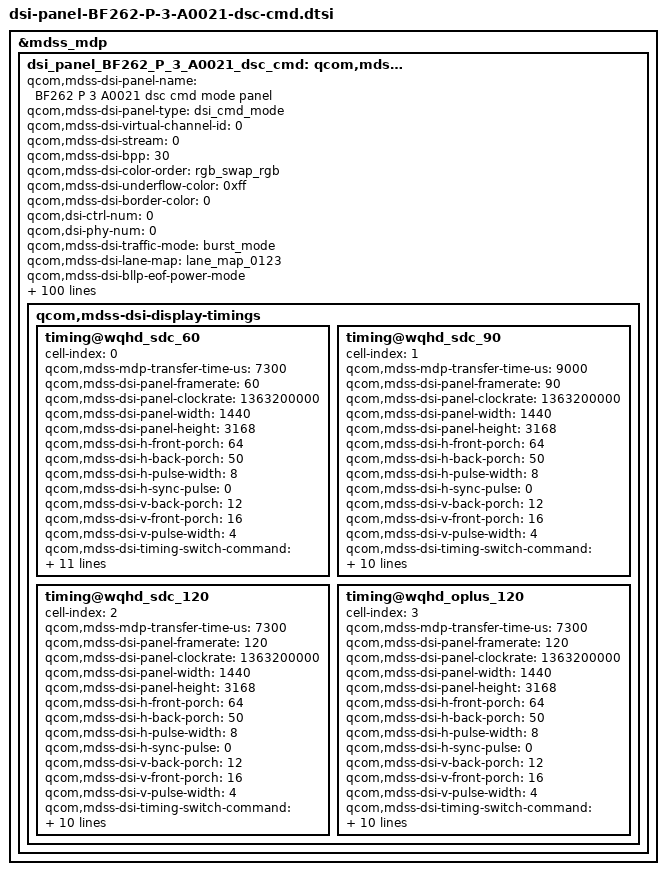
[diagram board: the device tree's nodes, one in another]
&mdss_mdp {
	dsi_panel_BF262_P_3_A0021_dsc_cmd: qcom,mdss_dsi_panel_BF262_P_3_A0021_dsc_cmd {
		qcom,mdss-dsi-panel-name = "BF262 P 3 A0021 dsc cmd mode panel";
		qcom,mdss-dsi-panel-type = "dsi_cmd_mode";
		qcom,mdss-dsi-virtual-channel-id = <0>;
		qcom,mdss-dsi-stream = <0>;
		qcom,mdss-dsi-bpp = <30>;
		qcom,mdss-dsi-color-order = "rgb_swap_rgb";
		qcom,mdss-dsi-underflow-color = <0xff>;
		qcom,mdss-dsi-border-color = <0>;
		qcom,dsi-ctrl-num = <0>;
		qcom,dsi-phy-num = <0>;
		qcom,mdss-dsi-traffic-mode = "burst_mode";
		qcom,mdss-dsi-lane-map = "lane_map_0123";
		qcom,mdss-dsi-bllp-eof-power-mode;
		qcom,mdss-dsi-bllp-power-mode;
		qcom,mdss-dsi-lane-0-state;
		qcom,mdss-dsi-lane-1-state;
		qcom,mdss-dsi-lane-2-state;
		qcom,mdss-dsi-lane-3-state;
		qcom,mdss-dsi-dma-trigger = "trigger_sw";
		qcom,mdss-dsi-mdp-trigger = "none";
		qcom,mdss-dsi-reset-sequence = <1 10>, <0 5>, <1 30>;
		qcom,mdss-pan-physical-width-dimension = <71>;
		qcom,mdss-pan-physical-height-dimension = <158>;
		qcom,mdss-dsi-te-check-enable;
		qcom,mdss-dsi-te-using-te-pin;
		qcom,mdss-dsi-te-pin-select = <1>;
		qcom,mdss-dsi-te-dcs-command = <1>;
		qcom,mdss-dsi-wr-mem-start = <0x2C>;
		qcom,mdss-dsi-wr-mem-continue = <0x3C>;
		//qcom,mdss-dsi-lp11-init;
		qcom,mdss-dsi-init-delay-us = <1000>;
		qcom,mdss-dsi-panel-jitter = <0x4 0x1>;
		qcom,dynamic-mode-switch-enabled;
		qcom,dynamic-mode-switch-type = "dynamic-resolution-switch-immediate";
		/* HDR Setting */
		qcom,mdss-dsi-panel-hdr-enabled;
		qcom,mdss-dsi-panel-hdr-color-primaries = <15635 16450 34000 16000 13250 34500 7500 3000>;
		qcom,mdss-dsi-panel-peak-brightness = <14000000>;
		qcom,mdss-dsi-panel-average-brightness = <2000000>;
		qcom,mdss-dsi-panel-blackness-level = <2000>;

		qcom,mdss-dsi-display-timings {
			timing@wqhd_sdc_60 {
				#include "dsi-panel-BF262-P-3-A0021-common.dtsi"
				cell-index = <0>;
				qcom,mdss-mdp-transfer-time-us = <7300>;
				qcom,mdss-dsi-panel-framerate = <60>;
				qcom,mdss-dsi-panel-clockrate = <1363200000>;
				qcom,mdss-dsi-panel-width = <1440>;
				qcom,mdss-dsi-panel-height = <3168>;
				qcom,mdss-dsi-h-front-porch = <64>;
				qcom,mdss-dsi-h-back-porch = <50>;
				qcom,mdss-dsi-h-pulse-width = <8>;
				qcom,mdss-dsi-h-sync-pulse = <0>;
				qcom,mdss-dsi-v-back-porch = <12>;
				qcom,mdss-dsi-v-front-porch = <16>;
				qcom,mdss-dsi-v-pulse-width = <4>;

				qcom,mdss-dsi-timing-switch-command = [
					15 00 00 40 00 00 02 FE 98
					15 00 00 40 00 00 02 CB 02
					15 00 00 40 00 00 02 FE 00
					15 00 00 40 00 00 02 8A 11
					15 00 00 40 00 00 02 FE 44
					15 00 00 40 00 00 02 49 00
					15 00 00 40 00 00 02 4E 01
					15 00 00 40 00 00 02 FE 72
					15 00 00 40 00 00 02 F7 48
					// SA
					15 00 00 40 00 00 02 FE 40
					15 00 00 00 00 00 02 92 65
				];
				qcom,mdss-dsi-on-command = [
					15 00 00 40 00 00 02 FE 44
					15 00 00 40 00 00 02 00 88
					15 00 00 40 00 00 02 75 00
					15 00 00 40 00 00 02 01 02
					15 00 00 40 00 00 02 02 01
					15 00 00 40 00 00 02 03 33
					15 00 00 40 00 00 02 04 33
					15 00 00 40 00 00 02 05 05
					15 00 00 40 00 00 02 06 0B
					15 00 00 40 00 00 02 07 17
					15 00 00 40 00 00 02 08 77
					15 00 00 40 00 00 02 09 00
					15 00 00 40 00 00 02 0A 00
					15 00 00 40 00 00 02 0B 00
					15 00 00 40 00 00 02 0C 00
					15 00 00 40 00 00 02 0D 23
					15 00 00 40 00 00 02 0E 30
					15 00 00 40 00 00 02 0F 00
					15 00 00 40 00 00 02 10 00
					15 00 00 40 00 00 02 11 11
					15 00 00 40 00 00 02 12 11
					15 00 00 40 00 00 02 13 11
					15 00 00 40 00 00 02 14 11
					15 00 00 40 00 00 02 15 02
					15 00 00 40 00 00 02 16 08
					15 00 00 40 00 00 02 17 11
					15 00 00 40 00 00 02 18 59
					15 00 00 40 00 00 02 19 00
					15 00 00 40 00 00 02 1A 00
					15 00 00 40 00 00 02 1B 00
					15 00 00 40 00 00 02 1C 00
					15 00 00 40 00 00 02 1D 23
					15 00 00 40 00 00 02 1E 30
					15 00 00 40 00 00 02 1F 11
					15 00 00 40 00 00 02 20 11
					15 00 00 40 00 00 02 21 11
					15 00 00 40 00 00 02 22 11
					15 00 00 40 00 00 02 23 11
					15 00 00 40 00 00 02 24 11
					15 00 00 40 00 00 02 25 05
					15 00 00 40 00 00 02 26 0B
					15 00 00 40 00 00 02 27 17
					15 00 00 40 00 00 02 28 77
					15 00 00 40 00 00 02 29 00
					15 00 00 40 00 00 02 2A 00
					15 00 00 40 00 00 02 2B 00
					15 00 00 40 00 00 02 2D 00
					15 00 00 40 00 00 02 2F 23
					15 00 00 40 00 00 02 30 30
					15 00 00 40 00 00 02 31 00
					15 00 00 40 00 00 02 32 00
					15 00 00 40 00 00 02 33 11
					15 00 00 40 00 00 02 34 11
					15 00 00 40 00 00 02 35 11
					15 00 00 40 00 00 02 36 11
					15 00 00 40 00 00 02 37 02
					15 00 00 40 00 00 02 38 08
					15 00 00 40 00 00 02 39 11
					15 00 00 40 00 00 02 3A 59
					15 00 00 40 00 00 02 3B 00
					15 00 00 40 00 00 02 3D 00
					15 00 00 40 00 00 02 3F 00
					15 00 00 40 00 00 02 40 00
					15 00 00 40 00 00 02 41 23
					15 00 00 40 00 00 02 42 30
					15 00 00 40 00 00 02 43 11
					15 00 00 40 00 00 02 44 11
					15 00 00 40 00 00 02 45 11
					15 00 00 40 00 00 02 46 11
					15 00 00 40 00 00 02 47 11
					15 00 00 40 00 00 02 48 11
					15 00 00 40 00 00 02 69 00
					15 00 00 40 00 00 02 6A 00
					15 00 00 40 00 00 02 6B 00
					15 00 00 40 00 00 02 6C 00
					15 00 00 40 00 00 02 6D 00
					15 00 00 40 00 00 02 6E 00
					15 00 00 40 00 00 02 6F 00
					15 00 00 40 00 00 02 70 00
					15 00 00 40 00 00 02 80 47
					15 00 00 40 00 00 02 81 02
					15 00 00 40 00 00 02 82 05
					15 00 00 40 00 00 02 83 1D
					15 00 00 40 00 00 02 84 00
					15 00 00 40 00 00 02 85 00
					15 00 00 40 00 00 02 86 00
					15 00 00 40 00 00 02 87 00
					15 00 00 40 00 00 02 88 00
					15 00 00 40 00 00 02 89 00
					15 00 00 40 00 00 02 8A 00
					15 00 00 40 00 00 02 8B 21
					15 00 00 40 00 00 02 8C 10
					15 00 00 40 00 00 02 8D 00
					15 00 00 40 00 00 02 8E 00
					15 00 00 40 00 00 02 8F 11
					15 00 00 40 00 00 02 90 11
					15 00 00 40 00 00 02 91 11
					15 00 00 40 00 00 02 92 11
					15 00 00 40 00 00 02 49 0B
					15 00 00 40 00 00 02 4A 06
					15 00 00 40 00 00 02 4B C0
					15 00 00 40 00 00 02 4C 00
					15 00 00 40 00 00 02 4D 00
					15 00 00 40 00 00 02 4E 00
					15 00 00 40 00 00 02 4F 00
					15 00 00 40 00 00 02 50 00
					15 00 00 40 00 00 02 51 00
					15 00 00 40 00 00 02 52 77
					15 00 00 40 00 00 02 53 59
					15 00 00 40 00 00 02 54 77
					15 00 00 40 00 00 02 55 59
					15 00 00 40 00 00 02 56 00
					15 00 00 40 00 00 02 58 00
					15 00 00 40 00 00 02 59 00
					15 00 00 40 00 00 02 5A 00
					15 00 00 40 00 00 02 5B 00
					15 00 00 40 00 00 02 5C 00
					15 00 00 40 00 00 02 5D 00
					15 00 00 40 00 00 02 71 00
					15 00 00 40 00 00 02 72 00
					15 00 00 40 00 00 02 73 00
					15 00 00 40 00 00 02 74 00
					15 00 00 40 00 00 02 5E 00
					15 00 00 40 00 00 02 5F 00
					15 00 00 40 00 00 02 60 00
					15 00 00 40 00 00 02 61 12
					15 00 00 40 00 00 02 62 30
					15 00 00 40 00 00 02 63 00
					15 00 00 40 00 00 02 64 00
					15 00 00 40 00 00 02 65 00
					15 00 00 40 00 00 02 76 C2
					15 00 00 40 00 00 02 77 E8
					15 00 00 40 00 00 02 FE 43
					15 00 00 40 00 00 02 64 15
					15 00 00 40 00 00 02 63 FE
					15 00 00 40 00 00 02 66 00
					15 00 00 40 00 00 02 67 11
					15 00 00 40 00 00 02 68 11
					15 00 00 40 00 00 02 69 33
					15 00 00 40 00 00 02 6A 33
					15 00 00 40 00 00 02 6B 00
					15 00 00 40 00 00 02 6C 00
					15 00 00 40 00 00 02 6D 00
					15 00 00 40 00 00 02 6E 00
					15 00 00 40 00 00 02 6F 00
					15 00 00 40 00 00 02 70 00
					15 00 00 40 00 00 02 71 00
					15 00 00 40 00 00 02 72 00
					15 00 00 40 00 00 02 73 00
					15 00 00 40 00 00 02 74 00
					15 00 00 40 00 00 02 75 00
					15 00 00 40 00 00 02 76 00
					15 00 00 40 00 00 02 77 00
					15 00 00 40 00 00 02 78 00
					15 00 00 40 00 00 02 79 00
					15 00 00 40 00 00 02 7A 00
					15 00 00 40 00 00 02 7B 00
					15 00 00 40 00 00 02 7C 00
					15 00 00 40 00 00 02 7D 00
					15 00 00 40 00 00 02 7E 00
					15 00 00 40 00 00 02 7F 00
					15 00 00 40 00 00 02 80 00
					15 00 00 40 00 00 02 81 00
					15 00 00 40 00 00 02 82 00
					15 00 00 40 00 00 02 83 00
					15 00 00 40 00 00 02 84 00
					15 00 00 40 00 00 02 85 00
					15 00 00 40 00 00 02 86 00
					15 00 00 40 00 00 02 87 00
					15 00 00 40 00 00 02 88 00
					15 00 00 40 00 00 02 89 00
					15 00 00 40 00 00 02 8A 00
					15 00 00 40 00 00 02 8B 21
					15 00 00 40 00 00 02 8C 16
					15 00 00 40 00 00 02 8D 0B
					15 00 00 40 00 00 02 8E 00
					15 00 00 40 00 00 02 8F 00
					15 00 00 40 00 00 02 90 00
					15 00 00 40 00 00 02 91 00
					15 00 00 40 00 00 02 92 00
					15 00 00 40 00 00 02 93 00
					15 00 00 40 00 00 02 94 00
					15 00 00 40 00 00 02 95 00
					15 00 00 40 00 00 02 96 00
					15 00 00 40 00 00 02 97 00
					15 00 00 40 00 00 02 98 00
					15 00 00 40 00 00 02 99 00
					15 00 00 40 00 00 02 9A 00
					15 00 00 40 00 00 02 9B 00
					15 00 00 40 00 00 02 9C 00
					15 00 00 40 00 00 02 9D 00
					15 00 00 40 00 00 02 9E 00
					15 00 00 40 00 00 02 9F 00
					15 00 00 40 00 00 02 A0 00
					15 00 00 40 00 00 02 A2 00
					15 00 00 40 00 00 02 A3 00
					15 00 00 40 00 00 02 A4 00
					15 00 00 40 00 00 02 A5 00
					15 00 00 40 00 00 02 A6 00
					15 00 00 40 00 00 02 A7 00
					15 00 00 40 00 00 02 A9 00
					15 00 00 40 00 00 02 AA 00
					15 00 00 40 00 00 02 AB 00
					15 00 00 40 00 00 02 AC 00
					15 00 00 40 00 00 02 AD 21
					15 00 00 40 00 00 02 AE 16
					15 00 00 40 00 00 02 AF 0B
					15 00 00 40 00 00 02 B0 00
					15 00 00 40 00 00 02 B1 00
					15 00 00 40 00 00 02 B2 00
					15 00 00 40 00 00 02 B3 00
					15 00 00 40 00 00 02 B4 00
					15 00 00 40 00 00 02 B5 00
					15 00 00 40 00 00 02 B6 00
					15 00 00 40 00 00 02 B7 00
					15 00 00 40 00 00 02 B8 00
					15 00 00 40 00 00 02 B9 00
					15 00 00 40 00 00 02 BA 00
					15 00 00 40 00 00 02 BB 00
					15 00 00 40 00 00 02 BC 00
					15 00 00 40 00 00 02 BD 00
					15 00 00 40 00 00 02 BE 00
					15 00 00 40 00 00 02 BF 00
					15 00 00 40 00 00 02 C0 00
					15 00 00 40 00 00 02 C1 00
					15 00 00 40 00 00 02 C2 00
					15 00 00 40 00 00 02 C3 00
					15 00 00 40 00 00 02 C4 00
					15 00 00 40 00 00 02 C5 00
					15 00 00 40 00 00 02 C6 00
					15 00 00 40 00 00 02 C7 00
					15 00 00 40 00 00 02 C8 00
					15 00 00 40 00 00 02 C9 00
					15 00 00 40 00 00 02 CA 00
					15 00 00 40 00 00 02 CB 00
					15 00 00 40 00 00 02 CC 00
					15 00 00 40 00 00 02 CD 21
					15 00 00 40 00 00 02 CE 16
					15 00 00 40 00 00 02 CF 0B
					15 00 00 40 00 00 02 D0 00
					15 00 00 40 00 00 02 D1 00
					15 00 00 40 00 00 02 D2 00
					15 00 00 40 00 00 02 D3 00
					15 00 00 40 00 00 02 D4 00
					15 00 00 40 00 00 02 D5 00
					15 00 00 40 00 00 02 D6 00
					15 00 00 40 00 00 02 D7 00
					15 00 00 40 00 00 02 D8 00
					15 00 00 40 00 00 02 D9 00
					15 00 00 40 00 00 02 DA 00
					15 00 00 40 00 00 02 DB 00
					15 00 00 40 00 00 02 DC 00
					15 00 00 40 00 00 02 DD 00
					15 00 00 40 00 00 02 DE 00
					15 00 00 40 00 00 02 DF 00
					15 00 00 40 00 00 02 E0 00
					15 00 00 40 00 00 02 E1 00
					15 00 00 40 00 00 02 E2 00
					15 00 00 40 00 00 02 E3 00
					15 00 00 40 00 00 02 E4 00
					15 00 00 40 00 00 02 E5 00
					15 00 00 40 00 00 02 E6 00
					15 00 00 40 00 00 02 E7 00
					15 00 00 40 00 00 02 E8 00
					15 00 00 40 00 00 02 E9 00
					15 00 00 40 00 00 02 EA 00
					15 00 00 40 00 00 02 EB 00
					15 00 00 40 00 00 02 EC 00
					15 00 00 40 00 00 02 FE 6A
					15 00 00 40 00 00 02 4E 00
					15 00 00 40 00 00 02 4F 00
					15 00 00 40 00 00 02 50 00
					15 00 00 40 00 00 02 51 00
					15 00 00 40 00 00 02 52 00
					15 00 00 40 00 00 02 53 00
					15 00 00 40 00 00 02 54 00
					15 00 00 40 00 00 02 55 00
					15 00 00 40 00 00 02 56 00
					15 00 00 40 00 00 02 58 00
					15 00 00 40 00 00 02 59 00
					15 00 00 40 00 00 02 5A 00
					15 00 00 40 00 00 02 5B 00
					15 00 00 40 00 00 02 5C 00
					15 00 00 40 00 00 02 5D 00
					15 00 00 40 00 00 02 5E 00
					15 00 00 40 00 00 02 FE 44
					15 00 00 40 00 00 02 78 07
					15 00 00 40 00 00 02 79 80
					15 00 00 40 00 00 02 66 00
					15 00 00 40 00 00 02 67 00
					15 00 00 40 00 00 02 FE 72
					15 00 00 40 00 00 02 F8 60
					15 00 00 40 00 00 02 33 03
					15 00 00 40 00 00 02 FE 98
					15 00 00 40 00 00 02 02 04
					15 00 00 40 00 00 02 03 68
					15 00 00 40 00 00 02 FE 40
					15 00 00 40 00 00 02 BC 02
					15 00 00 40 00 00 02 FE 98
					15 00 00 40 00 00 02 7D 10
					15 00 00 40 00 00 02 C4 8E
					15 00 00 40 00 00 02 FE 40
					15 00 00 40 00 00 02 92 65
					15 00 00 40 00 00 02 93 67
					15 00 00 40 00 00 02 FE 98
					15 00 00 40 00 00 02 CC 04
					15 00 00 40 00 00 02 CD 00
					15 00 00 40 00 00 02 CE E8
					15 00 00 40 00 00 02 CB 01
					15 00 00 40 00 00 02 C7 8A
					15 00 00 40 00 00 02 C6 80
					15 00 00 40 00 00 02 C5 00
					15 00 00 40 00 00 02 FE 98
					15 00 00 40 00 00 02 CB 01
					15 00 00 40 00 00 02 FE 45
					15 00 00 40 00 00 02 B2 78
					15 00 00 40 00 00 02 FE 72
					15 00 00 40 00 00 02 F7 48
					15 00 00 40 00 00 02 FE 00
					15 00 00 40 00 00 02 8A 11
					15 00 00 40 00 00 02 FE 44
					15 00 00 40 00 00 02 49 00
					15 00 00 40 00 00 02 4E 00
					15 00 00 40 00 00 02 FE 00
					15 00 00 40 00 00 02 2F 04
					15 00 00 40 00 00 02 FA 01
					15 00 00 40 00 00 02 C2 08
					15 00 00 40 00 00 02 35 00
					15 00 00 00 00 00 02 51 0D
					//60Hz
					/*ESD*/
					15 00 00 40 00 00 02 FE D4
					15 00 00 40 00 00 02 40 03
					15 00 00 40 00 00 02 FE FD
					15 00 00 40 00 00 02 80 06
					15 00 00 40 00 00 02 83 00
					15 00 00 40 00 00 02 FE A1
					15 00 00 40 00 00 02 B3 1F
					15 00 00 40 00 00 02 74 72
					15 00 00 40 00 00 02 C3 83
					15 00 00 40 00 00 02 C4 FF
					15 00 00 00 00 00 02 C5 7F
					//init code
					15 00 00 40 00 00 02 FE 42
					15 00 00 40 00 00 02 18 76
					15 00 00 40 00 00 02 FE 40
					15 00 00 40 00 00 02 BF BA
					15 00 00 40 00 00 02 FE 98
					15 00 00 40 00 00 02 2F 05
					15 00 00 40 00 00 02 FE 40
					15 00 00 40 00 00 02 BE 99
					15 00 00 40 00 00 02 FE 42
					15 00 00 40 00 00 02 1A 80
					15 00 00 40 00 00 02 19 00
					15 00 00 40 00 00 02 3B 65
					15 00 00 40 00 00 02 3D 00
					15 00 00 40 00 00 02 3F 00
					15 00 00 40 00 00 02 41 70
					15 00 00 40 00 00 02 43 00
					15 00 00 40 00 00 02 44 04
					15 00 00 40 00 00 02 FE 40
					15 00 00 40 00 00 02 64 60
					15 00 00 40 00 00 02 65 EC
					15 00 00 40 00 00 02 01 09
					15 00 00 40 00 00 02 FE D0
					15 00 00 40 00 00 02 86 14
					15 00 00 40 00 00 02 84 14
					15 00 00 40 00 00 02 85 01
					15 00 00 40 00 00 02 FE 99
					15 00 00 40 00 00 02 1B 14
					15 00 00 40 00 00 02 FE D0
					15 00 00 40 00 00 02 90 D0
					15 00 00 40 00 00 02 91 0A
					15 00 00 40 00 00 02 FE D4
					15 00 00 40 00 00 02 05 00
					15 00 00 40 00 00 02 FE D6
					15 00 00 40 00 00 02 17 00
					15 00 00 40 00 00 02 00 00
					15 00 00 40 00 00 02 09 00
					15 00 00 40 00 00 02 01 00
					15 00 00 40 00 00 02 02 FF
					15 00 00 40 00 00 02 05 FF
					15 00 00 40 00 00 02 03 0C
					15 00 00 40 00 00 02 04 02
					15 00 00 40 00 00 02 06 FF
					15 00 00 40 00 00 02 07 0C
					15 00 00 40 00 00 02 08 00
					15 00 00 40 00 00 02 FE 28
					15 00 00 40 00 00 02 05 01
					15 00 00 40 00 00 02 06 68
					15 00 00 40 00 00 02 FE 97
					15 00 00 40 00 00 02 40 01
					15 00 00 40 00 00 02 3D 05
					15 00 00 40 00 00 02 3F A0
					15 00 00 40 00 00 02 FE 1A
					15 00 00 40 00 00 02 04 01
					15 00 00 40 00 00 02 54 01
					15 00 00 40 00 00 02 FE 49
					15 00 00 40 00 00 02 5D 00
					15 00 00 40 00 00 02 54 17
					15 00 00 40 00 00 02 FE 1A
					15 00 00 40 00 00 02 62 80
					15 00 00 40 00 00 02 63 01
					15 00 00 40 00 00 02 64 01
					15 00 00 40 00 00 02 65 68
					15 00 00 40 00 00 02 36 50
					15 00 00 40 00 00 02 38 00
					15 00 00 40 00 00 02 1C 30
					15 00 00 40 00 00 02 FE 98
					15 00 00 40 00 00 02 0E A2
					15 00 00 40 00 00 02 FE 49
					15 00 00 40 00 00 02 79 81
					15 00 00 40 00 00 02 FE 1A
					15 00 00 40 00 00 02 34 13
					15 00 00 40 00 00 02 FE 49
					15 00 00 40 00 00 02 92 FF
					15 00 00 40 00 00 02 62 02
					15 00 00 40 00 00 02 63 01
					15 00 00 40 00 00 02 64 00
					15 00 00 40 00 00 02 0E 01
					15 00 00 40 00 00 02 11 22
					15 00 00 40 00 00 02 12 01
					15 00 00 40 00 00 02 B3 01
					15 00 00 40 00 00 02 68 09
					15 00 00 40 00 00 02 65 09
					15 00 00 40 00 00 02 66 09
					15 00 00 40 00 00 02 67 09
					15 00 00 40 00 00 02 0F 09
					15 00 00 40 00 00 02 6E 20
					15 00 00 40 00 00 02 72 58
					15 00 00 40 00 00 02 6D 00
					15 00 00 40 00 00 02 6F 58
					15 00 00 40 00 00 02 70 58
					15 00 00 40 00 00 02 71 58
					15 00 00 40 00 00 02 14 A9
					15 00 00 40 00 00 02 BD 01
					15 00 00 40 00 00 02 05 C1
					15 00 00 40 00 00 02 94 01
					15 00 00 40 00 00 02 06 C1
					15 00 00 40 00 00 02 B8 22
					15 00 00 40 00 00 02 BC 00
					15 00 00 40 00 00 02 BA 00
					15 00 00 40 00 00 02 1B 02
					15 00 00 40 00 00 02 1C 02
					15 00 00 40 00 00 02 1F 00
					15 00 00 40 00 00 02 20 00
					15 00 00 40 00 00 02 FE 98
					15 00 00 40 00 00 02 CF 00
					15 00 00 40 00 00 02 D0 AA
					15 00 00 40 00 00 02 FE 49
					15 00 00 40 00 00 02 9D 12
					15 00 00 40 00 00 02 B2 00
					15 00 00 40 00 00 02 FE D6
					15 00 00 40 00 00 02 9D 80
					15 00 00 40 00 00 02 FE 99
					15 00 00 40 00 00 02 1E 00
					15 00 00 40 00 00 02 1F 00
					15 00 00 40 00 00 02 FE 98
					15 00 00 40 00 00 02 0D C0
					15 00 00 40 00 00 02 FE D0
					15 00 00 40 00 00 02 C7 00
					15 00 00 40 00 00 02 C8 00
					15 00 00 40 00 00 02 FE 98
					15 00 00 40 00 00 02 0F FF
					15 00 00 40 00 00 02 FE 1A
					15 00 00 40 00 00 02 71 00
					15 00 00 40 00 00 02 FE 98
					15 00 00 40 00 00 02 11 08
					15 00 00 40 00 00 02 FE 72
					15 00 00 40 00 00 02 9B 00
					15 00 00 40 00 00 02 FE 6B
					15 00 00 40 00 00 02 03 10
					15 00 00 40 00 00 02 04 00
					15 00 00 40 00 00 02 FE 82
					15 00 00 40 00 00 02 C8 08
					15 00 00 40 00 00 02 FE 58
					15 00 00 40 00 00 02 C5 00
					15 00 00 40 00 00 02 FE D4
					15 00 00 40 00 00 02 04 06
					15 00 00 40 00 00 02 FE 98
					15 00 00 40 00 00 02 30 26
					15 00 00 40 00 00 02 31 80
					15 00 00 40 00 00 02 FE 49
					15 00 00 40 00 00 02 9D 12
					15 00 00 40 00 00 02 B2 08
					//ODC Off
					15 00 00 40 00 00 02 FE 82
					15 00 00 40 00 00 02 00 50
					//----Resolution_VESA END----
					15 00 00 40 00 00 02 FE D2
					15 00 00 40 00 00 02 97 00
					15 00 00 40 00 00 02 36 11
					15 00 00 40 00 00 02 39 AB
					15 00 00 40 00 00 02 3A 30
					15 00 00 40 00 00 02 3B 80
					15 00 00 40 00 00 02 3D 0C
					15 00 00 40 00 00 02 3F 60
					15 00 00 40 00 00 02 40 05
					15 00 00 40 00 00 02 41 A0
					15 00 00 40 00 00 02 42 00
					15 00 00 40 00 00 02 43 90
					15 00 00 40 00 00 02 44 02
					15 00 00 40 00 00 02 45 D0
					15 00 00 40 00 00 02 46 02
					15 00 00 40 00 00 02 47 D0
					15 00 00 40 00 00 02 48 02
					15 00 00 40 00 00 02 49 00
					15 00 00 40 00 00 02 4A 02
					15 00 00 40 00 00 02 4B 68
					15 00 00 40 00 00 02 4D 20
					15 00 00 40 00 00 02 4E 10
					15 00 00 40 00 00 02 4F 16
					15 00 00 40 00 00 02 50 00
					15 00 00 40 00 00 02 51 0A
					15 00 00 40 00 00 02 53 0C
					15 00 00 40 00 00 02 54 00
					15 00 00 40 00 00 02 55 AC
					15 00 00 40 00 00 02 56 00
					15 00 00 40 00 00 02 58 88
					15 00 00 40 00 00 02 59 18
					15 00 00 40 00 00 02 5A 00
					15 00 00 40 00 00 02 5B 10
					15 00 00 40 00 00 02 5C F0
					15 00 00 40 00 00 02 5D 07
					15 00 00 40 00 00 02 5E 10
					15 00 00 40 00 00 02 5F 20
					15 00 00 40 00 00 02 60 00
					15 00 00 40 00 00 02 61 06
					15 00 00 40 00 00 02 62 0F
					15 00 00 40 00 00 02 63 0F
					15 00 00 40 00 00 02 64 33
					15 00 00 40 00 00 02 65 0E
					15 00 00 40 00 00 02 66 1C
					15 00 00 40 00 00 02 67 2A
					15 00 00 40 00 00 02 68 38
					15 00 00 40 00 00 02 69 46
					15 00 00 40 00 00 02 6A 54
					15 00 00 40 00 00 02 6B 62
					15 00 00 40 00 00 02 6C 69
					15 00 00 40 00 00 02 6D 70
					15 00 00 40 00 00 02 6E 77
					15 00 00 40 00 00 02 6F 79
					15 00 00 40 00 00 02 70 7B
					15 00 00 40 00 00 02 71 7D
					15 00 00 40 00 00 02 72 7E
					15 00 00 40 00 00 02 73 02
					15 00 00 40 00 00 02 74 02
					15 00 00 40 00 00 02 75 22
					15 00 00 40 00 00 02 76 00
					15 00 00 40 00 00 02 77 2A
					15 00 00 40 00 00 02 78 40
					15 00 00 40 00 00 02 79 2A
					15 00 00 40 00 00 02 7A BE
					15 00 00 40 00 00 02 7B 3A
					15 00 00 40 00 00 02 7C FC
					15 00 00 40 00 00 02 7D 3A
					15 00 00 40 00 00 02 7E FA
					15 00 00 40 00 00 02 7F 3A
					15 00 00 40 00 00 02 80 F8
					15 00 00 40 00 00 02 81 3B
					15 00 00 40 00 00 02 82 38
					15 00 00 40 00 00 02 83 3B
					15 00 00 40 00 00 02 84 78
					15 00 00 40 00 00 02 85 3B
					15 00 00 40 00 00 02 86 B6
					15 00 00 40 00 00 02 87 4B
					15 00 00 40 00 00 02 88 F6
					15 00 00 40 00 00 02 89 4C
					15 00 00 40 00 00 02 8A 34
					15 00 00 40 00 00 02 8B 4C
					15 00 00 40 00 00 02 8C 74
					15 00 00 40 00 00 02 8D 5C
					15 00 00 40 00 00 02 8E 74
					15 00 00 40 00 00 02 8F 8C
					15 00 00 40 00 00 02 90 F4
					15 00 00 40 00 00 02 91 00
					15 00 00 40 00 00 02 92 00
					15 00 00 40 00 00 02 93 00
					15 00 00 40 00 00 02 94 00
					15 00 00 40 00 00 02 95 00
					15 00 00 40 00 00 02 96 00
					//sikp frame
					15 00 00 40 00 00 02 FE 98
					15 00 00 40 00 00 02 7D 10
					15 00 00 40 00 00 02 C4 88
					15 00 00 40 00 00 02 CC 00
					15 00 00 40 00 00 02 CD 02
					15 00 00 40 00 00 02 CE A8
					15 00 00 40 00 00 02 CB 01
					15 00 00 40 00 00 02 FE 40
					15 00 00 40 00 00 02 BC 02
					15 00 00 40 00 00 02 92 65
					15 00 00 00 00 00 02 93 76
					//Page 00
					15 00 00 40 00 00 02 FE 00
					//120HZ(3+18)
					15 00 00 40 00 00 02 8A 11
					15 00 00 40 00 00 02 2F 04
					//01=VESA ON  07=VESA OFF
					15 00 00 40 00 00 02 FA 01
					15 00 00 40 00 00 02 C2 08
					15 00 00 40 00 00 02 35 00
					39 00 00 00 00 00 03 51 0A 81
					//switch 60Hz
					//ODC Off
					15 00 00 40 00 00 02 FE 82
					15 00 00 40 00 00 02 00 50
					//switch
					15 00 00 40 00 00 02 FE 00
					15 00 00 40 00 00 02 8A 11
					// 15 00 00 40 00 00 02 38 00
					15 00 00 40 00 00 02 FE 72
					15 00 00 40 00 00 02 F7 48
					15 00 00 40 00 00 02 FE 44
					15 00 00 40 00 00 02 49 00
					15 00 00 40 00 00 02 4E 01
					15 00 00 00 00 00 02 FE 00

					// for te add
					15 00 00 40 00 00 02 FE 40
					15 00 00 40 00 00 02 BC 02 //SKIP_M 1:0
					15 00 00 40 00 00 02 FE 98
					15 00 00 40 00 00 02 7D 10 //te_allon =1
					15 00 00 40 00 00 02 C4 8E //bit7 te_on //
					15 00 00 40 00 00 02 FE 40
					15 00 00 40 00 00 02 92 65 // TE0/TE1
					15 00 00 40 00 00 02 93 67
					15 00 00 40 00 00 02 FE 98
					15 00 00 40 00 00 02 CC 04 //TE0_sel
					15 00 00 40 00 00 02 CD 00 //01 //TE1_sel
					15 00 00 40 00 00 02 CE E8
					15 00 00 40 00 00 02 CB 01 //60Hz ,01 120Hz
					15 00 00 40 00 00 02 C7 8A //60Hz VFP
					15 00 00 40 00 00 02 C6 80 //啟動st開關
					15 00 00 00 00 00 02 C5 00
					//for 60Hz TE
					15 00 00 40 00 00 02 FE 98
					15 00 00 40 00 00 02 CB 02 //60Hz 
					15 00 00 40 00 00 02 FE 45
					15 00 00 40 00 00 02 B2 78 //FF
					15 00 00 40 00 00 02 FE 44
					15 00 00 40 00 00 02 49 00 //HFR1 en
					15 00 00 40 00 00 02 4E 01 //LSB下限60hz
					15 00 00 40 00 00 02 FE 00
					15 00 00 00 00 00 02 8A 11 //固定

					15 00 00 00 00 00 02 FE 00
					05 00 00 00 64 00 01 11
					05 00 00 00 00 00 01 29
				];

				//qcom,panel-roi-alignment=<1080 44 1080 44 1080 44>;
				//qcom,partial-update-enabled = "single_roi";

				qcom,lm-split = <720 720>;
				qcom,mdss-dsc-slice-height = <22>;
				qcom,mdss-dsc-slice-width = <720>;
				oplus,apollo-panel-async-bl-delay = <9000>;
			};
			timing@wqhd_sdc_90 {
				#include "dsi-panel-BF262-P-3-A0021-common.dtsi"
				cell-index = <1>;
				qcom,mdss-mdp-transfer-time-us = <9000>;
				qcom,mdss-dsi-panel-framerate = <90>;
				qcom,mdss-dsi-panel-clockrate = <1363200000>;
				qcom,mdss-dsi-panel-width = <1440>;
				qcom,mdss-dsi-panel-height = <3168>;
				qcom,mdss-dsi-h-front-porch = <64>;
				qcom,mdss-dsi-h-back-porch = <50>;
				qcom,mdss-dsi-h-pulse-width = <8>;
				qcom,mdss-dsi-h-sync-pulse = <0>;
				qcom,mdss-dsi-v-back-porch = <12>;
				qcom,mdss-dsi-v-front-porch = <16>;
				qcom,mdss-dsi-v-pulse-width = <4>;

				qcom,mdss-dsi-timing-switch-command = [
					//SA-90Hz
					15 00 00 40 00 00 02 FE 98
					15 00 00 40 00 00 02 CB 01
					15 00 00 40 00 00 02 FE 00
					15 00 00 40 00 00 02 8A 11
					15 00 00 40 00 00 02 FE 44
					15 00 00 40 00 00 02 49 10
					15 00 00 40 00 00 02 4E 00
					15 00 00 40 00 00 02 FE 72
					15 00 00 00 00 00 02 F7 48
					// SA
					15 00 00 40 00 00 02 FE 40
					15 00 00 00 00 00 02 92 65
				];
				qcom,mdss-dsi-on-command = [
					15 00 00 40 00 00 02 FE 44
					15 00 00 40 00 00 02 00 88
					15 00 00 40 00 00 02 75 00
					15 00 00 40 00 00 02 01 02
					15 00 00 40 00 00 02 02 01
					15 00 00 40 00 00 02 03 33
					15 00 00 40 00 00 02 04 33
					15 00 00 40 00 00 02 05 05
					15 00 00 40 00 00 02 06 0B
					15 00 00 40 00 00 02 07 17
					15 00 00 40 00 00 02 08 77
					15 00 00 40 00 00 02 09 00
					15 00 00 40 00 00 02 0A 00
					15 00 00 40 00 00 02 0B 00
					15 00 00 40 00 00 02 0C 00
					15 00 00 40 00 00 02 0D 23
					15 00 00 40 00 00 02 0E 30
					15 00 00 40 00 00 02 0F 00
					15 00 00 40 00 00 02 10 00
					15 00 00 40 00 00 02 11 11
					15 00 00 40 00 00 02 12 11
					15 00 00 40 00 00 02 13 11
					15 00 00 40 00 00 02 14 11
					15 00 00 40 00 00 02 15 02
					15 00 00 40 00 00 02 16 08
					15 00 00 40 00 00 02 17 11
					15 00 00 40 00 00 02 18 59
					15 00 00 40 00 00 02 19 00
					15 00 00 40 00 00 02 1A 00
					15 00 00 40 00 00 02 1B 00
					15 00 00 40 00 00 02 1C 00
					15 00 00 40 00 00 02 1D 23
					15 00 00 40 00 00 02 1E 30
					15 00 00 40 00 00 02 1F 11
					15 00 00 40 00 00 02 20 11
					15 00 00 40 00 00 02 21 11
					15 00 00 40 00 00 02 22 11
					15 00 00 40 00 00 02 23 11
					15 00 00 40 00 00 02 24 11
					15 00 00 40 00 00 02 25 05
					15 00 00 40 00 00 02 26 0B
					15 00 00 40 00 00 02 27 17
					15 00 00 40 00 00 02 28 77
					15 00 00 40 00 00 02 29 00
					15 00 00 40 00 00 02 2A 00
					15 00 00 40 00 00 02 2B 00
					15 00 00 40 00 00 02 2D 00
					15 00 00 40 00 00 02 2F 23
					15 00 00 40 00 00 02 30 30
					15 00 00 40 00 00 02 31 00
					15 00 00 40 00 00 02 32 00
					15 00 00 40 00 00 02 33 11
					15 00 00 40 00 00 02 34 11
					15 00 00 40 00 00 02 35 11
					15 00 00 40 00 00 02 36 11
					15 00 00 40 00 00 02 37 02
					15 00 00 40 00 00 02 38 08
					15 00 00 40 00 00 02 39 11
					15 00 00 40 00 00 02 3A 59
					15 00 00 40 00 00 02 3B 00
					15 00 00 40 00 00 02 3D 00
					15 00 00 40 00 00 02 3F 00
					15 00 00 40 00 00 02 40 00
					15 00 00 40 00 00 02 41 23
					15 00 00 40 00 00 02 42 30
					15 00 00 40 00 00 02 43 11
					15 00 00 40 00 00 02 44 11
					15 00 00 40 00 00 02 45 11
					15 00 00 40 00 00 02 46 11
					15 00 00 40 00 00 02 47 11
					15 00 00 40 00 00 02 48 11
					15 00 00 40 00 00 02 69 00
					15 00 00 40 00 00 02 6A 00
					15 00 00 40 00 00 02 6B 00
					15 00 00 40 00 00 02 6C 00
					15 00 00 40 00 00 02 6D 00
					15 00 00 40 00 00 02 6E 00
					15 00 00 40 00 00 02 6F 00
					15 00 00 40 00 00 02 70 00
					15 00 00 40 00 00 02 80 47
					15 00 00 40 00 00 02 81 02
					15 00 00 40 00 00 02 82 05
					15 00 00 40 00 00 02 83 1D
					15 00 00 40 00 00 02 84 00
					15 00 00 40 00 00 02 85 00
					15 00 00 40 00 00 02 86 00
					15 00 00 40 00 00 02 87 00
					15 00 00 40 00 00 02 88 00
					15 00 00 40 00 00 02 89 00
					15 00 00 40 00 00 02 8A 00
					15 00 00 40 00 00 02 8B 21
					15 00 00 40 00 00 02 8C 10
					15 00 00 40 00 00 02 8D 00
					15 00 00 40 00 00 02 8E 00
					15 00 00 40 00 00 02 8F 11
					15 00 00 40 00 00 02 90 11
					15 00 00 40 00 00 02 91 11
					15 00 00 40 00 00 02 92 11
					15 00 00 40 00 00 02 49 0B
					15 00 00 40 00 00 02 4A 06
					15 00 00 40 00 00 02 4B C0
					15 00 00 40 00 00 02 4C 00
					15 00 00 40 00 00 02 4D 00
					15 00 00 40 00 00 02 4E 00
					15 00 00 40 00 00 02 4F 00
					15 00 00 40 00 00 02 50 00
					15 00 00 40 00 00 02 51 00
					15 00 00 40 00 00 02 52 77
					15 00 00 40 00 00 02 53 59
					15 00 00 40 00 00 02 54 77
					15 00 00 40 00 00 02 55 59
					15 00 00 40 00 00 02 56 00
					15 00 00 40 00 00 02 58 00
					15 00 00 40 00 00 02 59 00
					15 00 00 40 00 00 02 5A 00
					15 00 00 40 00 00 02 5B 00
					15 00 00 40 00 00 02 5C 00
					15 00 00 40 00 00 02 5D 00
					15 00 00 40 00 00 02 71 00
					15 00 00 40 00 00 02 72 00
					15 00 00 40 00 00 02 73 00
					15 00 00 40 00 00 02 74 00
					15 00 00 40 00 00 02 5E 00
					15 00 00 40 00 00 02 5F 00
					15 00 00 40 00 00 02 60 00
					15 00 00 40 00 00 02 61 12
					15 00 00 40 00 00 02 62 30
					15 00 00 40 00 00 02 63 00
					15 00 00 40 00 00 02 64 00
					15 00 00 40 00 00 02 65 00
					15 00 00 40 00 00 02 76 C2
					15 00 00 40 00 00 02 77 E8
					15 00 00 40 00 00 02 FE 43
					15 00 00 40 00 00 02 64 15
					15 00 00 40 00 00 02 63 FE
					15 00 00 40 00 00 02 66 00
					15 00 00 40 00 00 02 67 11
					15 00 00 40 00 00 02 68 11
					15 00 00 40 00 00 02 69 33
					15 00 00 40 00 00 02 6A 33
					15 00 00 40 00 00 02 6B 00
					15 00 00 40 00 00 02 6C 00
					15 00 00 40 00 00 02 6D 00
					15 00 00 40 00 00 02 6E 00
					15 00 00 40 00 00 02 6F 00
					15 00 00 40 00 00 02 70 00
					15 00 00 40 00 00 02 71 00
					15 00 00 40 00 00 02 72 00
					15 00 00 40 00 00 02 73 00
					15 00 00 40 00 00 02 74 00
					15 00 00 40 00 00 02 75 00
					15 00 00 40 00 00 02 76 00
					15 00 00 40 00 00 02 77 00
					15 00 00 40 00 00 02 78 00
					15 00 00 40 00 00 02 79 00
					15 00 00 40 00 00 02 7A 00
					15 00 00 40 00 00 02 7B 00
					15 00 00 40 00 00 02 7C 00
					15 00 00 40 00 00 02 7D 00
					15 00 00 40 00 00 02 7E 00
					15 00 00 40 00 00 02 7F 00
					15 00 00 40 00 00 02 80 00
					15 00 00 40 00 00 02 81 00
					15 00 00 40 00 00 02 82 00
					15 00 00 40 00 00 02 83 00
					15 00 00 40 00 00 02 84 00
					15 00 00 40 00 00 02 85 00
					15 00 00 40 00 00 02 86 00
					15 00 00 40 00 00 02 87 00
					15 00 00 40 00 00 02 88 00
					15 00 00 40 00 00 02 89 00
					15 00 00 40 00 00 02 8A 00
					15 00 00 40 00 00 02 8B 21
					15 00 00 40 00 00 02 8C 16
					15 00 00 40 00 00 02 8D 0B
					15 00 00 40 00 00 02 8E 00
					15 00 00 40 00 00 02 8F 00
					15 00 00 40 00 00 02 90 00
					15 00 00 40 00 00 02 91 00
					15 00 00 40 00 00 02 92 00
					15 00 00 40 00 00 02 93 00
					15 00 00 40 00 00 02 94 00
					15 00 00 40 00 00 02 95 00
					15 00 00 40 00 00 02 96 00
					15 00 00 40 00 00 02 97 00
					15 00 00 40 00 00 02 98 00
					15 00 00 40 00 00 02 99 00
					15 00 00 40 00 00 02 9A 00
					15 00 00 40 00 00 02 9B 00
					15 00 00 40 00 00 02 9C 00
					15 00 00 40 00 00 02 9D 00
					15 00 00 40 00 00 02 9E 00
					15 00 00 40 00 00 02 9F 00
					15 00 00 40 00 00 02 A0 00
					15 00 00 40 00 00 02 A2 00
					15 00 00 40 00 00 02 A3 00
					15 00 00 40 00 00 02 A4 00
					15 00 00 40 00 00 02 A5 00
					15 00 00 40 00 00 02 A6 00
					15 00 00 40 00 00 02 A7 00
					15 00 00 40 00 00 02 A9 00
					15 00 00 40 00 00 02 AA 00
					15 00 00 40 00 00 02 AB 00
					15 00 00 40 00 00 02 AC 00
					15 00 00 40 00 00 02 AD 21
					15 00 00 40 00 00 02 AE 16
					15 00 00 40 00 00 02 AF 0B
					15 00 00 40 00 00 02 B0 00
					15 00 00 40 00 00 02 B1 00
					15 00 00 40 00 00 02 B2 00
					15 00 00 40 00 00 02 B3 00
					15 00 00 40 00 00 02 B4 00
					15 00 00 40 00 00 02 B5 00
					15 00 00 40 00 00 02 B6 00
					15 00 00 40 00 00 02 B7 00
					15 00 00 40 00 00 02 B8 00
					15 00 00 40 00 00 02 B9 00
					15 00 00 40 00 00 02 BA 00
					15 00 00 40 00 00 02 BB 00
					15 00 00 40 00 00 02 BC 00
					15 00 00 40 00 00 02 BD 00
					15 00 00 40 00 00 02 BE 00
					15 00 00 40 00 00 02 BF 00
					15 00 00 40 00 00 02 C0 00
					15 00 00 40 00 00 02 C1 00
					15 00 00 40 00 00 02 C2 00
					15 00 00 40 00 00 02 C3 00
					15 00 00 40 00 00 02 C4 00
					15 00 00 40 00 00 02 C5 00
					15 00 00 40 00 00 02 C6 00
					15 00 00 40 00 00 02 C7 00
					15 00 00 40 00 00 02 C8 00
					15 00 00 40 00 00 02 C9 00
					15 00 00 40 00 00 02 CA 00
					15 00 00 40 00 00 02 CB 00
					15 00 00 40 00 00 02 CC 00
					15 00 00 40 00 00 02 CD 21
					15 00 00 40 00 00 02 CE 16
					15 00 00 40 00 00 02 CF 0B
					15 00 00 40 00 00 02 D0 00
					15 00 00 40 00 00 02 D1 00
					15 00 00 40 00 00 02 D2 00
					15 00 00 40 00 00 02 D3 00
					15 00 00 40 00 00 02 D4 00
					15 00 00 40 00 00 02 D5 00
					15 00 00 40 00 00 02 D6 00
					15 00 00 40 00 00 02 D7 00
					15 00 00 40 00 00 02 D8 00
					15 00 00 40 00 00 02 D9 00
					15 00 00 40 00 00 02 DA 00
					15 00 00 40 00 00 02 DB 00
					15 00 00 40 00 00 02 DC 00
					15 00 00 40 00 00 02 DD 00
					15 00 00 40 00 00 02 DE 00
					15 00 00 40 00 00 02 DF 00
					15 00 00 40 00 00 02 E0 00
					15 00 00 40 00 00 02 E1 00
					15 00 00 40 00 00 02 E2 00
					15 00 00 40 00 00 02 E3 00
					15 00 00 40 00 00 02 E4 00
					15 00 00 40 00 00 02 E5 00
					15 00 00 40 00 00 02 E6 00
					15 00 00 40 00 00 02 E7 00
					15 00 00 40 00 00 02 E8 00
					15 00 00 40 00 00 02 E9 00
					15 00 00 40 00 00 02 EA 00
					15 00 00 40 00 00 02 EB 00
					15 00 00 40 00 00 02 EC 00
					15 00 00 40 00 00 02 FE 6A
					15 00 00 40 00 00 02 4E 00
					15 00 00 40 00 00 02 4F 00
					15 00 00 40 00 00 02 50 00
					15 00 00 40 00 00 02 51 00
					15 00 00 40 00 00 02 52 00
					15 00 00 40 00 00 02 53 00
					15 00 00 40 00 00 02 54 00
					15 00 00 40 00 00 02 55 00
					15 00 00 40 00 00 02 56 00
					15 00 00 40 00 00 02 58 00
					15 00 00 40 00 00 02 59 00
					15 00 00 40 00 00 02 5A 00
					15 00 00 40 00 00 02 5B 00
					15 00 00 40 00 00 02 5C 00
					15 00 00 40 00 00 02 5D 00
					15 00 00 40 00 00 02 5E 00
					15 00 00 40 00 00 02 FE 44
					15 00 00 40 00 00 02 78 07
					15 00 00 40 00 00 02 79 80
					15 00 00 40 00 00 02 66 00
					15 00 00 40 00 00 02 67 00
					15 00 00 40 00 00 02 FE 72
					15 00 00 40 00 00 02 F8 60
					15 00 00 40 00 00 02 33 03
					15 00 00 40 00 00 02 FE 98
					15 00 00 40 00 00 02 02 04
					15 00 00 40 00 00 02 03 68
					15 00 00 40 00 00 02 FE 40
					15 00 00 40 00 00 02 BC 02
					15 00 00 40 00 00 02 FE 98
					15 00 00 40 00 00 02 7D 10
					15 00 00 40 00 00 02 C4 8E
					15 00 00 40 00 00 02 FE 40
					15 00 00 40 00 00 02 92 65
					15 00 00 40 00 00 02 93 67
					15 00 00 40 00 00 02 FE 98
					15 00 00 40 00 00 02 CC 04
					15 00 00 40 00 00 02 CD 00
					15 00 00 40 00 00 02 CE E8
					15 00 00 40 00 00 02 CB 01
					15 00 00 40 00 00 02 C7 8A
					15 00 00 40 00 00 02 C6 80
					15 00 00 40 00 00 02 C5 00
					15 00 00 40 00 00 02 FE 98
					15 00 00 40 00 00 02 CB 01
					15 00 00 40 00 00 02 FE 45
					15 00 00 40 00 00 02 B2 78
					15 00 00 40 00 00 02 FE 72
					15 00 00 40 00 00 02 F7 48
					15 00 00 40 00 00 02 FE 00
					15 00 00 40 00 00 02 8A 11
					15 00 00 40 00 00 02 FE 44
					15 00 00 40 00 00 02 49 00
					15 00 00 40 00 00 02 4E 00
					15 00 00 40 00 00 02 FE 00
					15 00 00 40 00 00 02 2F 04
					15 00 00 40 00 00 02 FA 01
					15 00 00 40 00 00 02 C2 08
					15 00 00 40 00 00 02 35 00
					15 00 00 00 00 00 02 51 0D
					/*ESD*/
					15 00 00 40 00 00 02 FE D4
					15 00 00 40 00 00 02 40 03
					15 00 00 40 00 00 02 FE FD
					15 00 00 40 00 00 02 80 06
					15 00 00 40 00 00 02 83 00
					15 00 00 40 00 00 02 FE A1
					15 00 00 40 00 00 02 B3 1F
					15 00 00 40 00 00 02 74 72
					15 00 00 40 00 00 02 C3 83
					15 00 00 40 00 00 02 C4 FF
					15 00 00 00 00 00 02 C5 7F
					// Init code
					15 00 00 40 00 00 02 FE 42
					15 00 00 40 00 00 02 18 76
					15 00 00 40 00 00 02 FE 40
					15 00 00 40 00 00 02 BF BA
					15 00 00 40 00 00 02 FE 98
					15 00 00 40 00 00 02 2F 05
					15 00 00 40 00 00 02 FE 40
					15 00 00 40 00 00 02 BE 99
					15 00 00 40 00 00 02 FE 42
					15 00 00 40 00 00 02 1A 80
					15 00 00 40 00 00 02 19 00
					15 00 00 40 00 00 02 3B 65
					15 00 00 40 00 00 02 3D 00
					15 00 00 40 00 00 02 3F 00
					15 00 00 40 00 00 02 41 70
					15 00 00 40 00 00 02 43 00
					15 00 00 40 00 00 02 44 04
					15 00 00 40 00 00 02 FE 40
					15 00 00 40 00 00 02 64 60
					15 00 00 40 00 00 02 65 EC
					15 00 00 40 00 00 02 01 09
					15 00 00 40 00 00 02 FE D0
					15 00 00 40 00 00 02 86 14
					15 00 00 40 00 00 02 84 14
					15 00 00 40 00 00 02 85 01
					15 00 00 40 00 00 02 FE 99
					15 00 00 40 00 00 02 1B 14
					15 00 00 40 00 00 02 FE D0
					15 00 00 40 00 00 02 90 D0
					15 00 00 40 00 00 02 91 0A
					15 00 00 40 00 00 02 FE D4
					15 00 00 40 00 00 02 05 00
					15 00 00 40 00 00 02 FE D6
					15 00 00 40 00 00 02 17 00
					15 00 00 40 00 00 02 00 00
					15 00 00 40 00 00 02 09 00
					15 00 00 40 00 00 02 01 00
					15 00 00 40 00 00 02 02 FF
					15 00 00 40 00 00 02 05 FF
					15 00 00 40 00 00 02 03 0C
					15 00 00 40 00 00 02 04 02
					15 00 00 40 00 00 02 06 FF
					15 00 00 40 00 00 02 07 0C
					15 00 00 40 00 00 02 08 00
					15 00 00 40 00 00 02 FE 28
					15 00 00 40 00 00 02 05 01
					15 00 00 40 00 00 02 06 68
					15 00 00 40 00 00 02 FE 97
					15 00 00 40 00 00 02 40 01
					15 00 00 40 00 00 02 3D 05
					15 00 00 40 00 00 02 3F A0
					15 00 00 40 00 00 02 FE 1A
					15 00 00 40 00 00 02 04 01
					15 00 00 40 00 00 02 54 01
					15 00 00 40 00 00 02 FE 49
					15 00 00 40 00 00 02 5D 00
					15 00 00 40 00 00 02 54 17
					15 00 00 40 00 00 02 FE 1A
					15 00 00 40 00 00 02 62 80
					15 00 00 40 00 00 02 63 01
					15 00 00 40 00 00 02 64 01
					15 00 00 40 00 00 02 65 68
					15 00 00 40 00 00 02 36 50
					15 00 00 40 00 00 02 38 00
					15 00 00 40 00 00 02 1C 30
					15 00 00 40 00 00 02 FE 98
					15 00 00 40 00 00 02 0E A2
					15 00 00 40 00 00 02 FE 49
					15 00 00 40 00 00 02 79 81
					15 00 00 40 00 00 02 FE 1A
					15 00 00 40 00 00 02 34 13
					15 00 00 40 00 00 02 FE 49
					15 00 00 40 00 00 02 92 FF
					15 00 00 40 00 00 02 62 02
					15 00 00 40 00 00 02 63 01
					15 00 00 40 00 00 02 64 00
					15 00 00 40 00 00 02 0E 01
					15 00 00 40 00 00 02 11 22
					15 00 00 40 00 00 02 12 01
					15 00 00 40 00 00 02 B3 01
					15 00 00 40 00 00 02 68 09
					15 00 00 40 00 00 02 65 09
					15 00 00 40 00 00 02 66 09
					15 00 00 40 00 00 02 67 09
					15 00 00 40 00 00 02 0F 09
					15 00 00 40 00 00 02 6E 20
					15 00 00 40 00 00 02 72 58
					15 00 00 40 00 00 02 6D 00
					15 00 00 40 00 00 02 6F 58
					15 00 00 40 00 00 02 70 58
					15 00 00 40 00 00 02 71 58
					15 00 00 40 00 00 02 14 A9
					15 00 00 40 00 00 02 BD 01
					15 00 00 40 00 00 02 05 C1
					15 00 00 40 00 00 02 94 01
					15 00 00 40 00 00 02 06 C1
					15 00 00 40 00 00 02 B8 22
					15 00 00 40 00 00 02 BC 00
					15 00 00 40 00 00 02 BA 00
					15 00 00 40 00 00 02 1B 02
					15 00 00 40 00 00 02 1C 02
					15 00 00 40 00 00 02 1F 00
					15 00 00 40 00 00 02 20 00
					15 00 00 40 00 00 02 FE 98
					15 00 00 40 00 00 02 CF 00
					15 00 00 40 00 00 02 D0 AA
					15 00 00 40 00 00 02 FE 49
					15 00 00 40 00 00 02 9D 12
					15 00 00 40 00 00 02 B2 00
					15 00 00 40 00 00 02 FE D6
					15 00 00 40 00 00 02 9D 80
					15 00 00 40 00 00 02 FE 99
					15 00 00 40 00 00 02 1E 00
					15 00 00 40 00 00 02 1F 00
					15 00 00 40 00 00 02 FE 98
					15 00 00 40 00 00 02 0D C0
					15 00 00 40 00 00 02 FE D0
					15 00 00 40 00 00 02 C7 00
					15 00 00 40 00 00 02 C8 00
					15 00 00 40 00 00 02 FE 98
					15 00 00 40 00 00 02 0F FF
					15 00 00 40 00 00 02 FE 1A
					15 00 00 40 00 00 02 71 00
					15 00 00 40 00 00 02 FE 98
					15 00 00 40 00 00 02 11 08
					15 00 00 40 00 00 02 FE 72
					15 00 00 40 00 00 02 9B 00
					15 00 00 40 00 00 02 FE 6B
					15 00 00 40 00 00 02 03 10
					15 00 00 40 00 00 02 04 00
					15 00 00 40 00 00 02 FE 82
					15 00 00 40 00 00 02 C8 08
					15 00 00 40 00 00 02 FE 58
					15 00 00 40 00 00 02 C5 00
					15 00 00 40 00 00 02 FE D4
					15 00 00 40 00 00 02 04 06
					15 00 00 40 00 00 02 FE 98
					15 00 00 40 00 00 02 30 26
					15 00 00 40 00 00 02 31 80
					15 00 00 40 00 00 02 FE 49
					15 00 00 40 00 00 02 9D 12
					15 00 00 40 00 00 02 B2 08
					//ODC Off
					15 00 00 40 00 00 02 FE 82
					15 00 00 40 00 00 02 00 50
					15 00 00 40 00 00 02 FE D2
					15 00 00 40 00 00 02 97 00
					15 00 00 40 00 00 02 36 11
					15 00 00 40 00 00 02 39 AB
					15 00 00 40 00 00 02 3A 30
					15 00 00 40 00 00 02 3B 80
					15 00 00 40 00 00 02 3D 0C
					15 00 00 40 00 00 02 3F 60
					15 00 00 40 00 00 02 40 05
					15 00 00 40 00 00 02 41 A0
					15 00 00 40 00 00 02 42 00
					15 00 00 40 00 00 02 43 90
					15 00 00 40 00 00 02 44 02
					15 00 00 40 00 00 02 45 D0
					15 00 00 40 00 00 02 46 02
					15 00 00 40 00 00 02 47 D0
					15 00 00 40 00 00 02 48 02
					15 00 00 40 00 00 02 49 00
					15 00 00 40 00 00 02 4A 02
					15 00 00 40 00 00 02 4B 68
					15 00 00 40 00 00 02 4D 20
					15 00 00 40 00 00 02 4E 10
					15 00 00 40 00 00 02 4F 16
					15 00 00 40 00 00 02 50 00
					15 00 00 40 00 00 02 51 0A
					15 00 00 40 00 00 02 53 0C
					15 00 00 40 00 00 02 54 00
					15 00 00 40 00 00 02 55 AC
					15 00 00 40 00 00 02 56 00
					15 00 00 40 00 00 02 58 88
					15 00 00 40 00 00 02 59 18
					15 00 00 40 00 00 02 5A 00
					15 00 00 40 00 00 02 5B 10
					15 00 00 40 00 00 02 5C F0
					15 00 00 40 00 00 02 5D 07
					15 00 00 40 00 00 02 5E 10
					15 00 00 40 00 00 02 5F 20
					15 00 00 40 00 00 02 60 00
					15 00 00 40 00 00 02 61 06
					15 00 00 40 00 00 02 62 0F
					15 00 00 40 00 00 02 63 0F
					15 00 00 40 00 00 02 64 33
					15 00 00 40 00 00 02 65 0E
					15 00 00 40 00 00 02 66 1C
					15 00 00 40 00 00 02 67 2A
					15 00 00 40 00 00 02 68 38
					15 00 00 40 00 00 02 69 46
					15 00 00 40 00 00 02 6A 54
					15 00 00 40 00 00 02 6B 62
					15 00 00 40 00 00 02 6C 69
					15 00 00 40 00 00 02 6D 70
					15 00 00 40 00 00 02 6E 77
					15 00 00 40 00 00 02 6F 79
					15 00 00 40 00 00 02 70 7B
					15 00 00 40 00 00 02 71 7D
					15 00 00 40 00 00 02 72 7E
					15 00 00 40 00 00 02 73 02
					15 00 00 40 00 00 02 74 02
					15 00 00 40 00 00 02 75 22
					15 00 00 40 00 00 02 76 00
					15 00 00 40 00 00 02 77 2A
					15 00 00 40 00 00 02 78 40
					15 00 00 40 00 00 02 79 2A
					15 00 00 40 00 00 02 7A BE
					15 00 00 40 00 00 02 7B 3A
					15 00 00 40 00 00 02 7C FC
					15 00 00 40 00 00 02 7D 3A
					15 00 00 40 00 00 02 7E FA
					15 00 00 40 00 00 02 7F 3A
					15 00 00 40 00 00 02 80 F8
					15 00 00 40 00 00 02 81 3B
					15 00 00 40 00 00 02 82 38
					15 00 00 40 00 00 02 83 3B
					15 00 00 40 00 00 02 84 78
					15 00 00 40 00 00 02 85 3B
					15 00 00 40 00 00 02 86 B6
					15 00 00 40 00 00 02 87 4B
					15 00 00 40 00 00 02 88 F6
					15 00 00 40 00 00 02 89 4C
					15 00 00 40 00 00 02 8A 34
					15 00 00 40 00 00 02 8B 4C
					15 00 00 40 00 00 02 8C 74
					15 00 00 40 00 00 02 8D 5C
					15 00 00 40 00 00 02 8E 74
					15 00 00 40 00 00 02 8F 8C
					15 00 00 40 00 00 02 90 F4
					15 00 00 40 00 00 02 91 00
					15 00 00 40 00 00 02 92 00
					15 00 00 40 00 00 02 93 00
					15 00 00 40 00 00 02 94 00
					15 00 00 40 00 00 02 95 00
					15 00 00 40 00 00 02 96 00
					//sikp frame
					15 00 00 40 00 00 02 FE 98
					15 00 00 40 00 00 02 7D 10
					15 00 00 40 00 00 02 C4 88
					15 00 00 40 00 00 02 CC 00
					15 00 00 40 00 00 02 CD 02
					15 00 00 40 00 00 02 CE A8
					15 00 00 40 00 00 02 CB 01
					15 00 00 40 00 00 02 FE 40
					15 00 00 40 00 00 02 BC 02
					15 00 00 40 00 00 02 92 65
					15 00 00 00 00 00 02 93 76
					//Page 00
					15 00 00 40 00 00 02 FE 00
					//120HZ(3+18)
					15 00 00 40 00 00 02 8A 11
					15 00 00 40 00 00 02 2F 04
					//01=VESA ON  07=VESA OFF
					15 00 00 40 00 00 02 FA 01
					15 00 00 40 00 00 02 C2 08
					15 00 00 40 00 00 02 35 00
					39 00 00 00 00 00 03 51 0A 81
					//switch 90Hz
					//ODC Off
					15 00 00 40 00 00 02 FE 82
					15 00 00 40 00 00 02 00 50
					//switch
					15 00 00 40 00 00 02 FE 00
					15 00 00 40 00 00 02 8A 11
					15 00 00 40 00 00 02 FE 72
					15 00 00 40 00 00 02 F7 48
					15 00 00 40 00 00 02 FE 44
					15 00 00 40 00 00 02 49 10
					15 00 00 40 00 00 02 4E 00
					15 00 00 00 00 00 02 FE 00

					// for te add
					15 00 00 40 00 00 02 FE 40
					15 00 00 40 00 00 02 BC 02 //SKIP_M 1:0
					15 00 00 40 00 00 02 FE 98
					15 00 00 40 00 00 02 7D 10 //te_allon =1
					15 00 00 40 00 00 02 C4 8E //bit7 te_on //
					15 00 00 40 00 00 02 FE 40
					15 00 00 40 00 00 02 92 65 // TE0/TE1
					15 00 00 40 00 00 02 93 67
					15 00 00 40 00 00 02 FE 98
					15 00 00 40 00 00 02 CC 04 //TE0_sel
					15 00 00 40 00 00 02 CD 00 //01 //TE1_sel
					15 00 00 40 00 00 02 CE E8
					15 00 00 40 00 00 02 CB 01 //60Hz ,01 120Hz
					15 00 00 40 00 00 02 C7 8A //60Hz VFP
					15 00 00 40 00 00 02 C6 80 //啟動st開關
					15 00 00 00 00 00 02 C5 00

					//for te add
					15 00 00 40 00 00 02 FE 98
					15 00 00 40 00 00 02 CB 01 //90Hz
					15 00 00 40 00 00 02 FE 45
					15 00 00 40 00 00 02 B2 78 //FF
					15 00 00 40 00 00 02 FE 44
					15 00 00 40 00 00 02 49 10 //HFR1 en
					15 00 00 40 00 00 02 4E 00 //LSB下限90hz
					15 00 00 40 00 00 02 FE 00
					15 00 00 00 00 00 02 8A 11 //固定

					15 00 00 00 00 00 02 FE 00
					05 00 00 00 64 00 01 11
					05 00 00 00 00 00 01 29
				];

				//qcom,panel-roi-alignment=<1080 44 1080 44 1080 44>;
				//qcom,partial-update-enabled = "single_roi";

				qcom,lm-split = <720 720>;
				qcom,mdss-dsc-slice-height = <22>;
				qcom,mdss-dsc-slice-width = <720>;
			};
			timing@wqhd_sdc_120 {
				#include "dsi-panel-BF262-P-3-A0021-common.dtsi"
				cell-index = <2>;
				qcom,mdss-mdp-transfer-time-us = <7300>;
				qcom,mdss-dsi-panel-framerate = <120>;
				qcom,mdss-dsi-panel-clockrate = <1363200000>;
				qcom,mdss-dsi-panel-width = <1440>;
				qcom,mdss-dsi-panel-height = <3168>;
				qcom,mdss-dsi-h-front-porch = <64>;
				qcom,mdss-dsi-h-back-porch = <50>;
				qcom,mdss-dsi-h-pulse-width = <8>;
				qcom,mdss-dsi-h-sync-pulse = <0>;
				qcom,mdss-dsi-v-back-porch = <12>;
				qcom,mdss-dsi-v-front-porch = <16>;
				qcom,mdss-dsi-v-pulse-width = <4>;

				qcom,mdss-dsi-timing-switch-command = [
					//120Hz
					//switch
					15 00 00 40 00 00 02 FE 98
					15 00 00 40 00 00 02 CB 01
					15 00 00 40 00 00 02 FE 00
					15 00 00 40 00 00 02 8A 11
					15 00 00 40 00 00 02 FE 44
					15 00 00 40 00 00 02 49 00
					15 00 00 40 00 00 02 4E 00
					15 00 00 40 00 00 02 FE 72
					15 00 00 00 00 00 02 F7 48
					// SA
					15 00 00 40 00 00 02 FE 40
					15 00 00 00 00 00 02 92 65
				];
				qcom,mdss-dsi-on-command = [
					15 00 00 40 00 00 02 FE 44
					15 00 00 40 00 00 02 00 88
					15 00 00 40 00 00 02 75 00
					15 00 00 40 00 00 02 01 02
					15 00 00 40 00 00 02 02 01
					15 00 00 40 00 00 02 03 33
					15 00 00 40 00 00 02 04 33
					15 00 00 40 00 00 02 05 05
					15 00 00 40 00 00 02 06 0B
					15 00 00 40 00 00 02 07 17
					15 00 00 40 00 00 02 08 77
					15 00 00 40 00 00 02 09 00
					15 00 00 40 00 00 02 0A 00
					15 00 00 40 00 00 02 0B 00
					15 00 00 40 00 00 02 0C 00
					15 00 00 40 00 00 02 0D 23
					15 00 00 40 00 00 02 0E 30
					15 00 00 40 00 00 02 0F 00
					15 00 00 40 00 00 02 10 00
					15 00 00 40 00 00 02 11 11
					15 00 00 40 00 00 02 12 11
					15 00 00 40 00 00 02 13 11
					15 00 00 40 00 00 02 14 11
					15 00 00 40 00 00 02 15 02
					15 00 00 40 00 00 02 16 08
					15 00 00 40 00 00 02 17 11
					15 00 00 40 00 00 02 18 59
					15 00 00 40 00 00 02 19 00
					15 00 00 40 00 00 02 1A 00
					15 00 00 40 00 00 02 1B 00
					15 00 00 40 00 00 02 1C 00
					15 00 00 40 00 00 02 1D 23
					15 00 00 40 00 00 02 1E 30
					15 00 00 40 00 00 02 1F 11
					15 00 00 40 00 00 02 20 11
					15 00 00 40 00 00 02 21 11
					15 00 00 40 00 00 02 22 11
					15 00 00 40 00 00 02 23 11
					15 00 00 40 00 00 02 24 11
					15 00 00 40 00 00 02 25 05
					15 00 00 40 00 00 02 26 0B
					15 00 00 40 00 00 02 27 17
					15 00 00 40 00 00 02 28 77
					15 00 00 40 00 00 02 29 00
					15 00 00 40 00 00 02 2A 00
					15 00 00 40 00 00 02 2B 00
					15 00 00 40 00 00 02 2D 00
					15 00 00 40 00 00 02 2F 23
					15 00 00 40 00 00 02 30 30
					15 00 00 40 00 00 02 31 00
					15 00 00 40 00 00 02 32 00
					15 00 00 40 00 00 02 33 11
					15 00 00 40 00 00 02 34 11
					15 00 00 40 00 00 02 35 11
					15 00 00 40 00 00 02 36 11
					15 00 00 40 00 00 02 37 02
					15 00 00 40 00 00 02 38 08
					15 00 00 40 00 00 02 39 11
					15 00 00 40 00 00 02 3A 59
					15 00 00 40 00 00 02 3B 00
					15 00 00 40 00 00 02 3D 00
					15 00 00 40 00 00 02 3F 00
					15 00 00 40 00 00 02 40 00
					15 00 00 40 00 00 02 41 23
					15 00 00 40 00 00 02 42 30
					15 00 00 40 00 00 02 43 11
					15 00 00 40 00 00 02 44 11
					15 00 00 40 00 00 02 45 11
					15 00 00 40 00 00 02 46 11
					15 00 00 40 00 00 02 47 11
					15 00 00 40 00 00 02 48 11
					15 00 00 40 00 00 02 69 00
					15 00 00 40 00 00 02 6A 00
					15 00 00 40 00 00 02 6B 00
					15 00 00 40 00 00 02 6C 00
					15 00 00 40 00 00 02 6D 00
					15 00 00 40 00 00 02 6E 00
					15 00 00 40 00 00 02 6F 00
					15 00 00 40 00 00 02 70 00
					15 00 00 40 00 00 02 80 47
					15 00 00 40 00 00 02 81 02
					15 00 00 40 00 00 02 82 05
					15 00 00 40 00 00 02 83 1D
					15 00 00 40 00 00 02 84 00
					15 00 00 40 00 00 02 85 00
					15 00 00 40 00 00 02 86 00
					15 00 00 40 00 00 02 87 00
					15 00 00 40 00 00 02 88 00
					15 00 00 40 00 00 02 89 00
					15 00 00 40 00 00 02 8A 00
					15 00 00 40 00 00 02 8B 21
					15 00 00 40 00 00 02 8C 10
					15 00 00 40 00 00 02 8D 00
					15 00 00 40 00 00 02 8E 00
					15 00 00 40 00 00 02 8F 11
					15 00 00 40 00 00 02 90 11
					15 00 00 40 00 00 02 91 11
					15 00 00 40 00 00 02 92 11
					15 00 00 40 00 00 02 49 0B
					15 00 00 40 00 00 02 4A 06
					15 00 00 40 00 00 02 4B C0
					15 00 00 40 00 00 02 4C 00
					15 00 00 40 00 00 02 4D 00
					15 00 00 40 00 00 02 4E 00
					15 00 00 40 00 00 02 4F 00
					15 00 00 40 00 00 02 50 00
					15 00 00 40 00 00 02 51 00
					15 00 00 40 00 00 02 52 77
					15 00 00 40 00 00 02 53 59
					15 00 00 40 00 00 02 54 77
					15 00 00 40 00 00 02 55 59
					15 00 00 40 00 00 02 56 00
					15 00 00 40 00 00 02 58 00
					15 00 00 40 00 00 02 59 00
					15 00 00 40 00 00 02 5A 00
					15 00 00 40 00 00 02 5B 00
					15 00 00 40 00 00 02 5C 00
					15 00 00 40 00 00 02 5D 00
					15 00 00 40 00 00 02 71 00
					15 00 00 40 00 00 02 72 00
					15 00 00 40 00 00 02 73 00
					15 00 00 40 00 00 02 74 00
					15 00 00 40 00 00 02 5E 00
					15 00 00 40 00 00 02 5F 00
					15 00 00 40 00 00 02 60 00
					15 00 00 40 00 00 02 61 12
					15 00 00 40 00 00 02 62 30
					15 00 00 40 00 00 02 63 00
					15 00 00 40 00 00 02 64 00
					15 00 00 40 00 00 02 65 00
					15 00 00 40 00 00 02 76 C2
					15 00 00 40 00 00 02 77 E8
					15 00 00 40 00 00 02 FE 43
					15 00 00 40 00 00 02 64 15
					15 00 00 40 00 00 02 63 FE
					15 00 00 40 00 00 02 66 00
					15 00 00 40 00 00 02 67 11
					15 00 00 40 00 00 02 68 11
					15 00 00 40 00 00 02 69 33
					15 00 00 40 00 00 02 6A 33
					15 00 00 40 00 00 02 6B 00
					15 00 00 40 00 00 02 6C 00
					15 00 00 40 00 00 02 6D 00
					15 00 00 40 00 00 02 6E 00
					15 00 00 40 00 00 02 6F 00
					15 00 00 40 00 00 02 70 00
					15 00 00 40 00 00 02 71 00
					15 00 00 40 00 00 02 72 00
					15 00 00 40 00 00 02 73 00
					15 00 00 40 00 00 02 74 00
					15 00 00 40 00 00 02 75 00
					15 00 00 40 00 00 02 76 00
					15 00 00 40 00 00 02 77 00
					15 00 00 40 00 00 02 78 00
					15 00 00 40 00 00 02 79 00
					15 00 00 40 00 00 02 7A 00
					15 00 00 40 00 00 02 7B 00
					15 00 00 40 00 00 02 7C 00
					15 00 00 40 00 00 02 7D 00
					15 00 00 40 00 00 02 7E 00
					15 00 00 40 00 00 02 7F 00
					15 00 00 40 00 00 02 80 00
					15 00 00 40 00 00 02 81 00
					15 00 00 40 00 00 02 82 00
					15 00 00 40 00 00 02 83 00
					15 00 00 40 00 00 02 84 00
					15 00 00 40 00 00 02 85 00
					15 00 00 40 00 00 02 86 00
					15 00 00 40 00 00 02 87 00
					15 00 00 40 00 00 02 88 00
					15 00 00 40 00 00 02 89 00
					15 00 00 40 00 00 02 8A 00
					15 00 00 40 00 00 02 8B 21
					15 00 00 40 00 00 02 8C 16
					15 00 00 40 00 00 02 8D 0B
					15 00 00 40 00 00 02 8E 00
					15 00 00 40 00 00 02 8F 00
					15 00 00 40 00 00 02 90 00
					15 00 00 40 00 00 02 91 00
					15 00 00 40 00 00 02 92 00
					15 00 00 40 00 00 02 93 00
					15 00 00 40 00 00 02 94 00
					15 00 00 40 00 00 02 95 00
					15 00 00 40 00 00 02 96 00
					15 00 00 40 00 00 02 97 00
					15 00 00 40 00 00 02 98 00
					15 00 00 40 00 00 02 99 00
					15 00 00 40 00 00 02 9A 00
					15 00 00 40 00 00 02 9B 00
					15 00 00 40 00 00 02 9C 00
					15 00 00 40 00 00 02 9D 00
					15 00 00 40 00 00 02 9E 00
					15 00 00 40 00 00 02 9F 00
					15 00 00 40 00 00 02 A0 00
					15 00 00 40 00 00 02 A2 00
					15 00 00 40 00 00 02 A3 00
					15 00 00 40 00 00 02 A4 00
					15 00 00 40 00 00 02 A5 00
					15 00 00 40 00 00 02 A6 00
					15 00 00 40 00 00 02 A7 00
					15 00 00 40 00 00 02 A9 00
					15 00 00 40 00 00 02 AA 00
					15 00 00 40 00 00 02 AB 00
					15 00 00 40 00 00 02 AC 00
					15 00 00 40 00 00 02 AD 21
					15 00 00 40 00 00 02 AE 16
					15 00 00 40 00 00 02 AF 0B
					15 00 00 40 00 00 02 B0 00
					15 00 00 40 00 00 02 B1 00
					15 00 00 40 00 00 02 B2 00
					15 00 00 40 00 00 02 B3 00
					15 00 00 40 00 00 02 B4 00
					15 00 00 40 00 00 02 B5 00
					15 00 00 40 00 00 02 B6 00
					15 00 00 40 00 00 02 B7 00
					15 00 00 40 00 00 02 B8 00
					15 00 00 40 00 00 02 B9 00
					15 00 00 40 00 00 02 BA 00
					15 00 00 40 00 00 02 BB 00
					15 00 00 40 00 00 02 BC 00
					15 00 00 40 00 00 02 BD 00
					15 00 00 40 00 00 02 BE 00
					15 00 00 40 00 00 02 BF 00
					15 00 00 40 00 00 02 C0 00
					15 00 00 40 00 00 02 C1 00
					15 00 00 40 00 00 02 C2 00
					15 00 00 40 00 00 02 C3 00
					15 00 00 40 00 00 02 C4 00
					15 00 00 40 00 00 02 C5 00
					15 00 00 40 00 00 02 C6 00
					15 00 00 40 00 00 02 C7 00
					15 00 00 40 00 00 02 C8 00
					15 00 00 40 00 00 02 C9 00
					15 00 00 40 00 00 02 CA 00
					15 00 00 40 00 00 02 CB 00
					15 00 00 40 00 00 02 CC 00
					15 00 00 40 00 00 02 CD 21
					15 00 00 40 00 00 02 CE 16
					15 00 00 40 00 00 02 CF 0B
					15 00 00 40 00 00 02 D0 00
					15 00 00 40 00 00 02 D1 00
					15 00 00 40 00 00 02 D2 00
					15 00 00 40 00 00 02 D3 00
					15 00 00 40 00 00 02 D4 00
					15 00 00 40 00 00 02 D5 00
					15 00 00 40 00 00 02 D6 00
					15 00 00 40 00 00 02 D7 00
					15 00 00 40 00 00 02 D8 00
					15 00 00 40 00 00 02 D9 00
					15 00 00 40 00 00 02 DA 00
					15 00 00 40 00 00 02 DB 00
					15 00 00 40 00 00 02 DC 00
					15 00 00 40 00 00 02 DD 00
					15 00 00 40 00 00 02 DE 00
					15 00 00 40 00 00 02 DF 00
					15 00 00 40 00 00 02 E0 00
					15 00 00 40 00 00 02 E1 00
					15 00 00 40 00 00 02 E2 00
					15 00 00 40 00 00 02 E3 00
					15 00 00 40 00 00 02 E4 00
					15 00 00 40 00 00 02 E5 00
					15 00 00 40 00 00 02 E6 00
					15 00 00 40 00 00 02 E7 00
					15 00 00 40 00 00 02 E8 00
					15 00 00 40 00 00 02 E9 00
					15 00 00 40 00 00 02 EA 00
					15 00 00 40 00 00 02 EB 00
					15 00 00 40 00 00 02 EC 00
					15 00 00 40 00 00 02 FE 6A
					15 00 00 40 00 00 02 4E 00
					15 00 00 40 00 00 02 4F 00
					15 00 00 40 00 00 02 50 00
					15 00 00 40 00 00 02 51 00
					15 00 00 40 00 00 02 52 00
					15 00 00 40 00 00 02 53 00
					15 00 00 40 00 00 02 54 00
					15 00 00 40 00 00 02 55 00
					15 00 00 40 00 00 02 56 00
					15 00 00 40 00 00 02 58 00
					15 00 00 40 00 00 02 59 00
					15 00 00 40 00 00 02 5A 00
					15 00 00 40 00 00 02 5B 00
					15 00 00 40 00 00 02 5C 00
					15 00 00 40 00 00 02 5D 00
					15 00 00 40 00 00 02 5E 00
					15 00 00 40 00 00 02 FE 44
					15 00 00 40 00 00 02 78 07
					15 00 00 40 00 00 02 79 80
					15 00 00 40 00 00 02 66 00
					15 00 00 40 00 00 02 67 00
					15 00 00 40 00 00 02 FE 72
					15 00 00 40 00 00 02 F8 60
					15 00 00 40 00 00 02 33 03
					15 00 00 40 00 00 02 FE 98
					15 00 00 40 00 00 02 02 04
					15 00 00 40 00 00 02 03 68
					15 00 00 40 00 00 02 FE 40
					15 00 00 40 00 00 02 BC 02
					15 00 00 40 00 00 02 FE 98
					15 00 00 40 00 00 02 7D 10
					15 00 00 40 00 00 02 C4 8E
					15 00 00 40 00 00 02 FE 40
					15 00 00 40 00 00 02 92 65
					15 00 00 40 00 00 02 93 67
					15 00 00 40 00 00 02 FE 98
					15 00 00 40 00 00 02 CC 04
					15 00 00 40 00 00 02 CD 00
					15 00 00 40 00 00 02 CE E8
					15 00 00 40 00 00 02 CB 01
					15 00 00 40 00 00 02 C7 8A
					15 00 00 40 00 00 02 C6 80
					15 00 00 40 00 00 02 C5 00
					15 00 00 40 00 00 02 FE 98
					15 00 00 40 00 00 02 CB 01
					15 00 00 40 00 00 02 FE 45
					15 00 00 40 00 00 02 B2 78
					15 00 00 40 00 00 02 FE 72
					15 00 00 40 00 00 02 F7 48
					15 00 00 40 00 00 02 FE 00
					15 00 00 40 00 00 02 8A 11
					15 00 00 40 00 00 02 FE 44
					15 00 00 40 00 00 02 49 00
					15 00 00 40 00 00 02 4E 00
					15 00 00 40 00 00 02 FE 00
					15 00 00 40 00 00 02 2F 04
					15 00 00 40 00 00 02 FA 01
					15 00 00 40 00 00 02 C2 08
					15 00 00 40 00 00 02 35 00
					15 00 00 00 00 00 02 51 0D
					/*ESD*/
					15 00 00 40 00 00 02 FE D4
					15 00 00 40 00 00 02 40 03
					15 00 00 40 00 00 02 FE FD
					15 00 00 40 00 00 02 80 06
					15 00 00 40 00 00 02 83 00
					15 00 00 40 00 00 02 FE A1
					15 00 00 40 00 00 02 B3 1F
					15 00 00 40 00 00 02 74 72
					15 00 00 40 00 00 02 C3 83
					15 00 00 40 00 00 02 C4 FF
					15 00 00 00 00 00 02 C5 7F
					//init code
					15 00 00 40 00 00 02 FE 42
					15 00 00 40 00 00 02 18 76
					15 00 00 40 00 00 02 FE 40
					15 00 00 40 00 00 02 BF BA
					15 00 00 40 00 00 02 FE 98
					15 00 00 40 00 00 02 2F 05
					15 00 00 40 00 00 02 FE 40
					15 00 00 40 00 00 02 BE 99
					15 00 00 40 00 00 02 FE 42
					15 00 00 40 00 00 02 1A 80
					15 00 00 40 00 00 02 19 00
					15 00 00 40 00 00 02 3B 65
					15 00 00 40 00 00 02 3D 00
					15 00 00 40 00 00 02 3F 00
					15 00 00 40 00 00 02 41 70
					15 00 00 40 00 00 02 43 00
					15 00 00 40 00 00 02 44 04
					15 00 00 40 00 00 02 FE 40
					15 00 00 40 00 00 02 64 60
					15 00 00 40 00 00 02 65 EC
					15 00 00 40 00 00 02 01 09
					15 00 00 40 00 00 02 FE D0
					15 00 00 40 00 00 02 86 14
					15 00 00 40 00 00 02 84 14
					15 00 00 40 00 00 02 85 01
					15 00 00 40 00 00 02 FE 99
					15 00 00 40 00 00 02 1B 14
					15 00 00 40 00 00 02 FE D0
					15 00 00 40 00 00 02 90 D0
					15 00 00 40 00 00 02 91 0A
					15 00 00 40 00 00 02 FE D4
					15 00 00 40 00 00 02 05 00
					15 00 00 40 00 00 02 FE D6
					15 00 00 40 00 00 02 17 00
					15 00 00 40 00 00 02 00 00
					15 00 00 40 00 00 02 09 00
					15 00 00 40 00 00 02 01 00
					15 00 00 40 00 00 02 02 FF
					15 00 00 40 00 00 02 05 FF
					15 00 00 40 00 00 02 03 0C
					15 00 00 40 00 00 02 04 02
					15 00 00 40 00 00 02 06 FF
					15 00 00 40 00 00 02 07 0C
					15 00 00 40 00 00 02 08 00
					15 00 00 40 00 00 02 FE 28
					15 00 00 40 00 00 02 05 01
					15 00 00 40 00 00 02 06 68
					15 00 00 40 00 00 02 FE 97
					15 00 00 40 00 00 02 40 01
					15 00 00 40 00 00 02 3D 05
					15 00 00 40 00 00 02 3F A0
					15 00 00 40 00 00 02 FE 1A
					15 00 00 40 00 00 02 04 01
					15 00 00 40 00 00 02 54 01
					15 00 00 40 00 00 02 FE 49
					15 00 00 40 00 00 02 5D 00
					15 00 00 40 00 00 02 54 17
					15 00 00 40 00 00 02 FE 1A
					15 00 00 40 00 00 02 62 80
					15 00 00 40 00 00 02 63 01
					15 00 00 40 00 00 02 64 01
					15 00 00 40 00 00 02 65 68
					15 00 00 40 00 00 02 36 50
					15 00 00 40 00 00 02 38 00
					15 00 00 40 00 00 02 1C 30
					15 00 00 40 00 00 02 FE 98
					15 00 00 40 00 00 02 0E A2
					15 00 00 40 00 00 02 FE 49
					15 00 00 40 00 00 02 79 81
					15 00 00 40 00 00 02 FE 1A
					15 00 00 40 00 00 02 34 13
					15 00 00 40 00 00 02 FE 49
					15 00 00 40 00 00 02 92 FF
					15 00 00 40 00 00 02 62 02
					15 00 00 40 00 00 02 63 01
					15 00 00 40 00 00 02 64 00
					15 00 00 40 00 00 02 0E 01
					15 00 00 40 00 00 02 11 22
					15 00 00 40 00 00 02 12 01
					15 00 00 40 00 00 02 B3 01
					15 00 00 40 00 00 02 68 09
					15 00 00 40 00 00 02 65 09
					15 00 00 40 00 00 02 66 09
					15 00 00 40 00 00 02 67 09
					15 00 00 40 00 00 02 0F 09
					15 00 00 40 00 00 02 6E 20
					15 00 00 40 00 00 02 72 58
					15 00 00 40 00 00 02 6D 00
					15 00 00 40 00 00 02 6F 58
					15 00 00 40 00 00 02 70 58
					15 00 00 40 00 00 02 71 58
					15 00 00 40 00 00 02 14 A9
					15 00 00 40 00 00 02 BD 01
					15 00 00 40 00 00 02 05 C1
					15 00 00 40 00 00 02 94 01
					15 00 00 40 00 00 02 06 C1
					15 00 00 40 00 00 02 B8 22
					15 00 00 40 00 00 02 BC 00
					15 00 00 40 00 00 02 BA 00
					15 00 00 40 00 00 02 1B 02
					15 00 00 40 00 00 02 1C 02
					15 00 00 40 00 00 02 1F 00
					15 00 00 40 00 00 02 20 00
					15 00 00 40 00 00 02 FE 98
					15 00 00 40 00 00 02 CF 00
					15 00 00 40 00 00 02 D0 AA
					15 00 00 40 00 00 02 FE 49
					15 00 00 40 00 00 02 9D 12
					15 00 00 40 00 00 02 B2 00
					15 00 00 40 00 00 02 FE D6
					15 00 00 40 00 00 02 9D 80
					15 00 00 40 00 00 02 FE 99
					15 00 00 40 00 00 02 1E 00
					15 00 00 40 00 00 02 1F 00
					15 00 00 40 00 00 02 FE 98
					15 00 00 40 00 00 02 0D C0
					15 00 00 40 00 00 02 FE D0
					15 00 00 40 00 00 02 C7 00
					15 00 00 40 00 00 02 C8 00
					15 00 00 40 00 00 02 FE 98
					15 00 00 40 00 00 02 0F FF
					15 00 00 40 00 00 02 FE 1A
					15 00 00 40 00 00 02 71 00
					15 00 00 40 00 00 02 FE 98
					15 00 00 40 00 00 02 11 08
					15 00 00 40 00 00 02 FE 72
					15 00 00 40 00 00 02 9B 00
					15 00 00 40 00 00 02 FE 6B
					15 00 00 40 00 00 02 03 10
					15 00 00 40 00 00 02 04 00
					15 00 00 40 00 00 02 FE 82
					15 00 00 40 00 00 02 C8 08
					15 00 00 40 00 00 02 FE 58
					15 00 00 40 00 00 02 C5 00
					15 00 00 40 00 00 02 FE D4
					15 00 00 40 00 00 02 04 06
					15 00 00 40 00 00 02 FE 98
					15 00 00 40 00 00 02 30 26
					15 00 00 40 00 00 02 31 80
					15 00 00 40 00 00 02 FE 49
					15 00 00 40 00 00 02 9D 12
					15 00 00 40 00 00 02 B2 08
					//ODC Off
					15 00 00 40 00 00 02 FE 82
					15 00 00 40 00 00 02 00 50
					//----Resolution_VESA END----
					//switch to D2 page
					15 00 00 40 00 00 02 FE D2
					//08=pps 听IC   00=听AP
					15 00 00 40 00 00 02 97 00
					15 00 00 40 00 00 02 36 11
					15 00 00 40 00 00 02 39 AB
					15 00 00 40 00 00 02 3A 30
					15 00 00 40 00 00 02 3B 80
					15 00 00 40 00 00 02 3D 0C
					15 00 00 40 00 00 02 3F 60
					15 00 00 40 00 00 02 40 05
					15 00 00 40 00 00 02 41 A0
					15 00 00 40 00 00 02 42 00
					15 00 00 40 00 00 02 43 90
					15 00 00 40 00 00 02 44 02
					15 00 00 40 00 00 02 45 D0
					15 00 00 40 00 00 02 46 02
					15 00 00 40 00 00 02 47 D0
					15 00 00 40 00 00 02 48 02
					15 00 00 40 00 00 02 49 00
					15 00 00 40 00 00 02 4A 02
					15 00 00 40 00 00 02 4B 68
					15 00 00 40 00 00 02 4D 20
					15 00 00 40 00 00 02 4E 10
					15 00 00 40 00 00 02 4F 16
					15 00 00 40 00 00 02 50 00
					15 00 00 40 00 00 02 51 0A
					15 00 00 40 00 00 02 53 0C
					15 00 00 40 00 00 02 54 00
					15 00 00 40 00 00 02 55 AC
					15 00 00 40 00 00 02 56 00
					15 00 00 40 00 00 02 58 88
					15 00 00 40 00 00 02 59 18
					15 00 00 40 00 00 02 5A 00
					15 00 00 40 00 00 02 5B 10
					15 00 00 40 00 00 02 5C F0
					15 00 00 40 00 00 02 5D 07
					15 00 00 40 00 00 02 5E 10
					15 00 00 40 00 00 02 5F 20
					15 00 00 40 00 00 02 60 00
					15 00 00 40 00 00 02 61 06
					15 00 00 40 00 00 02 62 0F
					15 00 00 40 00 00 02 63 0F
					15 00 00 40 00 00 02 64 33
					15 00 00 40 00 00 02 65 0E
					15 00 00 40 00 00 02 66 1C
					15 00 00 40 00 00 02 67 2A
					15 00 00 40 00 00 02 68 38
					15 00 00 40 00 00 02 69 46
					15 00 00 40 00 00 02 6A 54
					15 00 00 40 00 00 02 6B 62
					15 00 00 40 00 00 02 6C 69
					15 00 00 40 00 00 02 6D 70
					15 00 00 40 00 00 02 6E 77
					15 00 00 40 00 00 02 6F 79
					15 00 00 40 00 00 02 70 7B
					15 00 00 40 00 00 02 71 7D
					15 00 00 40 00 00 02 72 7E
					15 00 00 40 00 00 02 73 02
					15 00 00 40 00 00 02 74 02
					15 00 00 40 00 00 02 75 22
					15 00 00 40 00 00 02 76 00
					15 00 00 40 00 00 02 77 2A
					15 00 00 40 00 00 02 78 40
					15 00 00 40 00 00 02 79 2A
					15 00 00 40 00 00 02 7A BE
					15 00 00 40 00 00 02 7B 3A
					15 00 00 40 00 00 02 7C FC
					15 00 00 40 00 00 02 7D 3A
					15 00 00 40 00 00 02 7E FA
					15 00 00 40 00 00 02 7F 3A
					15 00 00 40 00 00 02 80 F8
					15 00 00 40 00 00 02 81 3B
					15 00 00 40 00 00 02 82 38
					15 00 00 40 00 00 02 83 3B
					15 00 00 40 00 00 02 84 78
					15 00 00 40 00 00 02 85 3B
					15 00 00 40 00 00 02 86 B6
					15 00 00 40 00 00 02 87 4B
					15 00 00 40 00 00 02 88 F6
					15 00 00 40 00 00 02 89 4C
					15 00 00 40 00 00 02 8A 34
					15 00 00 40 00 00 02 8B 4C
					15 00 00 40 00 00 02 8C 74
					15 00 00 40 00 00 02 8D 5C
					15 00 00 40 00 00 02 8E 74
					15 00 00 40 00 00 02 8F 8C
					15 00 00 40 00 00 02 90 F4
					15 00 00 40 00 00 02 91 00
					15 00 00 40 00 00 02 92 00
					15 00 00 40 00 00 02 93 00
					15 00 00 40 00 00 02 94 00
					15 00 00 40 00 00 02 95 00
					15 00 00 40 00 00 02 96 00
					15 00 00 40 00 00 02 FE 00
					//sikp frame
					15 00 00 40 00 00 02 FE 98
					15 00 00 40 00 00 02 7D 10
					15 00 00 40 00 00 02 C4 88
					15 00 00 40 00 00 02 CC 00
					15 00 00 40 00 00 02 CD 02
					15 00 00 40 00 00 02 CE A8
					15 00 00 40 00 00 02 CB 01
					15 00 00 40 00 00 02 FE 40
					15 00 00 40 00 00 02 BC 02
					15 00 00 40 00 00 02 92 65
					15 00 00 00 00 00 02 93 76
					//Page 00
					15 00 00 40 00 00 02 FE 00
					15 00 00 40 00 00 02 8A 11
					//120HZ(3+18)
					15 00 00 40 00 00 02 2F 04
					15 00 00 40 00 00 02 FA 01
					//01=VESA ON  07=VESA OFF
					15 00 00 40 00 00 02 C2 08
					15 00 00 40 00 00 02 35 00
					39 00 00 40 00 00 03 51 0A 81
					//switch 120Hz
					//ODC Off
					15 00 00 40 00 00 02 FE 82
					15 00 00 40 00 00 02 00 50
					//switch
					15 00 00 40 00 00 02 FE 00
					15 00 00 40 00 00 02 8A 11
					15 00 00 40 00 00 02 FE 72
					15 00 00 40 00 00 02 F7 48
					15 00 00 40 00 00 02 FE 44
					15 00 00 40 00 00 02 49 00
					15 00 00 40 00 00 02 4E 00
					15 00 00 00 00 00 02 FE 00

					// for te add
					15 00 00 40 00 00 02 FE 40
					15 00 00 40 00 00 02 BC 02 //SKIP_M 1:0
					15 00 00 40 00 00 02 FE 98
					15 00 00 40 00 00 02 7D 10 //te_allon =1
					15 00 00 40 00 00 02 C4 8E //bit7 te_on //
					15 00 00 40 00 00 02 FE 40
					15 00 00 40 00 00 02 92 65 // TE0/TE1
					15 00 00 40 00 00 02 93 67
					15 00 00 40 00 00 02 FE 98
					15 00 00 40 00 00 02 CC 04 //TE0_sel
					15 00 00 40 00 00 02 CD 00 //01 //TE1_sel
					15 00 00 40 00 00 02 CE E8
					15 00 00 40 00 00 02 CB 01 //60Hz ,01 120Hz
					15 00 00 40 00 00 02 C7 8A //60Hz VFP
					15 00 00 40 00 00 02 C6 80 //啟動st開關
					15 00 00 00 00 00 02 C5 00

					//120Hz for te switch
					15 00 00 40 00 00 02 FE 98
					15 00 00 00 00 00 02 CB 01 //120Hz
					15 00 00 40 00 00 02 FE 45
					15 00 00 40 00 00 02 B2 78 //FF
					15 00 00 40 00 00 02 FE 44
					15 00 00 40 00 00 02 49 00 //HFR1 en
					15 00 00 40 00 00 02 4E 00 //LSB下限120hz
					15 00 00 40 00 00 02 FE 00
					15 00 00 00 00 00 02 8A 11 //固定

					15 00 00 00 00 00 02 FE 00
					05 00 00 00 64 00 01 11
					05 00 00 00 00 00 01 29
				];

				//qcom,panel-roi-alignment=<1080 44 1080 44 1080 44>;
				//qcom,partial-update-enabled = "single_roi";

				qcom,lm-split = <720 720>;
				qcom,mdss-dsc-slice-height = <22>;
				qcom,mdss-dsc-slice-width = <720>;
			};
			timing@wqhd_oplus_120 {
				#include "dsi-panel-BF262-P-3-A0021-common.dtsi"
				cell-index = <3>;
				qcom,mdss-mdp-transfer-time-us = <7300>;
				qcom,mdss-dsi-panel-framerate = <120>;
				qcom,mdss-dsi-panel-clockrate = <1363200000>;
				qcom,mdss-dsi-panel-width = <1440>;
				qcom,mdss-dsi-panel-height = <3168>;
				qcom,mdss-dsi-h-front-porch = <64>;
				qcom,mdss-dsi-h-back-porch = <50>;
				qcom,mdss-dsi-h-pulse-width = <8>;
				qcom,mdss-dsi-h-sync-pulse = <0>;
				qcom,mdss-dsi-v-back-porch = <12>;
				qcom,mdss-dsi-v-front-porch = <16>;
				qcom,mdss-dsi-v-pulse-width = <4>;

				qcom,mdss-dsi-timing-switch-command = [
					//OA-120Hz + Single-TE
					39 00 00 40 00 00 04 FF 08 58 00
					15 00 00 40 00 00 02 5A 00
					15 00 00 40 00 00 02 5B 00
					15 00 00 40 00 00 02 5E 01
					15 00 00 40 00 00 02 60 02
					39 00 00 40 00 00 04 FF 08 58 20
					15 00 00 40 00 00 02 BD 45
					15 00 00 40 00 00 02 BE 65
					39 00 00 40 00 00 04 FF 08 58 02
					15 00 00 40 00 00 02 A7 00
					39 00 00 40 00 00 07 B0 00 00 80 00 00 10
					15 00 00 40 00 00 02 B6 20
					15 00 00 40 00 00 02 B8 03
					39 00 00 40 00 00 04 FF 08 58 2D
					15 00 00 40 00 00 02 80 40
					15 00 00 40 00 00 02 85 00
					15 00 00 40 00 00 02 93 00
					15 00 00 40 00 00 02 94 00
					15 00 00 40 00 00 02 95 01
					15 00 00 40 00 00 02 96 0D
					15 00 00 40 00 00 02 A0 00
					15 00 00 40 00 00 02 A1 00
					15 00 00 40 00 00 02 EB 00
					39 00 00 00 00 00 04 FF 08 58 00
				];
				qcom,mdss-dsi-on-command = [
					39 00 00 40 00 00 04 FF 5A A5 00
					15 00 00 40 00 00 02 5E 01
					15 00 00 40 00 00 02 60 00
					39 00 00 40 00 00 04 FF 5A A5 2D
					39 00 00 40 00 00 04 EC 01 0B 20
					39 00 00 40 00 00 03 93 84 00
					39 00 00 40 00 00 03 94 00 00
					39 00 00 40 00 00 03 95 00 00
					39 00 00 40 00 00 03 96 0C 00
					15 00 00 40 00 00 02 ED 03
					15 00 00 40 00 00 02 83 00
					15 00 00 40 00 00 02 F2 00
					39 00 00 40 00 00 04 FF 5A A5 02
					15 00 00 40 00 00 02 B6 00
					39 00 00 40 00 00 04 B0 01 80 00
					15 00 00 42 00 00 02 61 0D
					15 00 00 42 00 00 02 6D 01
					15 00 00 42 00 00 02 35 00
					15 00 00 42 00 00 02 53 20
					39 00 00 42 00 00 05 51 0D BB 0D BB
					15 00 00 42 78 00 02 11 00
					15 00 00 02 00 00 02 29 00
				];

				//qcom,panel-roi-alignment=<1080 44 1080 44 1080 44>;
				//qcom,partial-update-enabled = "single_roi";

				qcom,lm-split = <720 720>;
				qcom,mdss-dsc-slice-height = <22>;
				qcom,mdss-dsc-slice-width = <720>;
			};

		};
	};
};

&dsi_panel_BF262_P_3_A0021_dsc_cmd {
	qcom,ulps-enabled;
	qcom,dsi-select-clocks = "pll_byte_clk0", "pll_dsi_clk0";
	qcom,mdss-dsi-display-timings {
		timing@wqhd_sdc_60 {
			qcom,mdss-dsi-panel-phy-timings = [00 2C 0C 0C 1D 1A 0C 0C 0B 02 04 00 24 11];
			qcom,display-topology = <1 1 1>,<2 2 1>;
			qcom,default-topology-index = <1>;
		};
		timing@wqhd_sdc_90 {
			qcom,mdss-dsi-panel-phy-timings = [00 2C 0C 0C 1D 1A 0C 0C 0B 02 04 00 24 11];
			qcom,display-topology = <1 1 1>,<2 2 1>;
			qcom,default-topology-index = <1>;
		};
		timing@wqhd_sdc_120 {
			qcom,mdss-dsi-panel-phy-timings = [00 2C 0C 0C 1D 1A 0C 0C 0B 02 04 00 24 11];
			qcom,display-topology = <1 1 1>,<2 2 1>;
			qcom,default-topology-index = <1>;
		};
		timing@wqhd_oplus_120 {
			qcom,mdss-dsi-panel-phy-timings = [00 2C 0C 0C 1D 1A 0C 0C 0B 02 04 00 24 11];
			qcom,display-topology = <1 1 1>,<2 2 1>;
			qcom,default-topology-index = <1>;
		};
	};
};

&dsi_panel_BF262_P_3_A0021_dsc_cmd {
	/* HARDWARE CONFIG */
	qcom,panel-supply-entries = <&oplus_dsi_panel_custom_pwr_supply>;
	qcom,mdss-dsi-panel-controller = <&mdss_dsi0>;
	qcom,platform-te-gpio = <&tlmm 86 0>;
	qcom,platform-reset-gpio = <&tlmm 98 0>;
	oplus,panel-gpio1 = <&pm8550ve_f_gpios 7 0>;

	oplus,panel-reset-position = <0x02>;
	oplus,panel-power-on-sequence = "10", "vddio", "10", "gpio1", "10", "vci", "10";
	oplus,panel-power-off-sequence = "10", "vci", "10", "gpio1", "10", "vddio", "10";

	qcom,panel_voltage_vddi_name = "vddio";
	qcom,panel_voltage_vddi = <1 1750000 1850000 1950000>;
	qcom,panel_voltage_vddr_name = "vci";
	qcom,panel_voltage_vddr = <1 3000000 3200000 3300000>;

	//enable mipi strength
	oplus,enhance_mipi_strength;

	/* BRIGHTNESS CONFIG */
	qcom,mdss-dsi-bl-pmic-control-type = "bl_ctrl_dcs";
	qcom,bl-dsc-cmd-state = "dsi_hs_mode";
	qcom,mdss-dsi-bl-inverted-dbv;
	qcom,mdss-dsi-bl-min-level = <1>;
	qcom,mdss-dsi-bl-max-level = <4094>;
	qcom,mdss-brightness-max-level = <4094>;
	oplus,dsi-bl-normal-max-level = <3332>;
	oplus,dsi-brightness-normal-max-level = <3332>;
	oplus,dsi-brightness-default-level = <1433>;
	oplus,dsi-dc-backlight-threshold = <1102>;
	oplus,dsi-global-hbm-case-id = <1>;
	//oplus,dsi-global-hbm-case23-threshold = <2048>;

	/* ESD CONFIG */
//	qcom,esd-check-enabled;
	qcom,mdss-dsi-panel-status-check-mode = "reg_read";
	qcom,mdss-dsi-panel-status-command = [
		06 00 00 00 00 00 01 0A
		06 00 00 00 00 00 01 B0
	];
	qcom,mdss-dsi-panel-status-command-state = "dsi_lp_mode";
	qcom,mdss-dsi-panel-status-value = <
		0x9C 0x0F
		0x9C 0x05
	>;
	qcom,mdss-dsi-panel-status-read-length = <1 1>;
	oplus,mdss-dsi-panel-status-match-modes = <0x00000002>;

	/* FACTORY CONFIG */
	oplus,mdss-dsi-vendor-name = "A0005";
	oplus,mdss-dsi-manufacture = "P_3";
	oplus,color_vivid_status;
	oplus,color_srgb_status;
	oplus,color_softiris_status;
	//oplus,color_oplus_calibrate_status;
	oplus,color_dual_brightness_status;
	oplus,color_2nit_status;
	oplus,color_loading_status;
	oplus,color_nature_profession_status;
	oplus,mdss-dsi-panel-type = <0>;

	/* OPLUS FEATURES CONFIG */
	oplus,dp-enabled;
	//oplus,dsi-cabc-enabled;
	//oplus,dsi-dre-enabled;
	oplus,dsi-serial-number-enabled;
	oplus,dsi-serial-number-switch-page;
	oplus,dsi-serial-number-reg= <0x06>;
	oplus,dsi-serial-number-index= <0>;
	oplus,dsi-serial-number-read-count= <7>;

	/* adfr config */
	oplus,adfr-config = <0x000>;  // 0b0010'0000'0001
	oplus,adfr-test-te-gpio = <&tlmm 85 0>;
	/* just for qsync enable */
//	qcom,qsync-enable;
	qcom,mdss-dsi-qsync-min-refresh-rate = <24>;

	oplus,pwm-switch-support;
	oplus,pwm-switch-backlight-threshold = <1100>;
	oplus,pwm-onepulse-support;
	oplus,pwm-onepulse-backlight-threshold = <1100>;

	/* demura dbv config */
	oplus,bl_denura-dbv-switch-support;

	/* add for panel id compatibility */
	oplus,panel_init_compatibility_enable;

	/* ofp config */
	oplus,ofp-fp-type = <0x188>;
	oplus,ofp-need-to-bypass-gamut;
	oplus,ofp-need-to-wait-data-before-aod-on;
};
